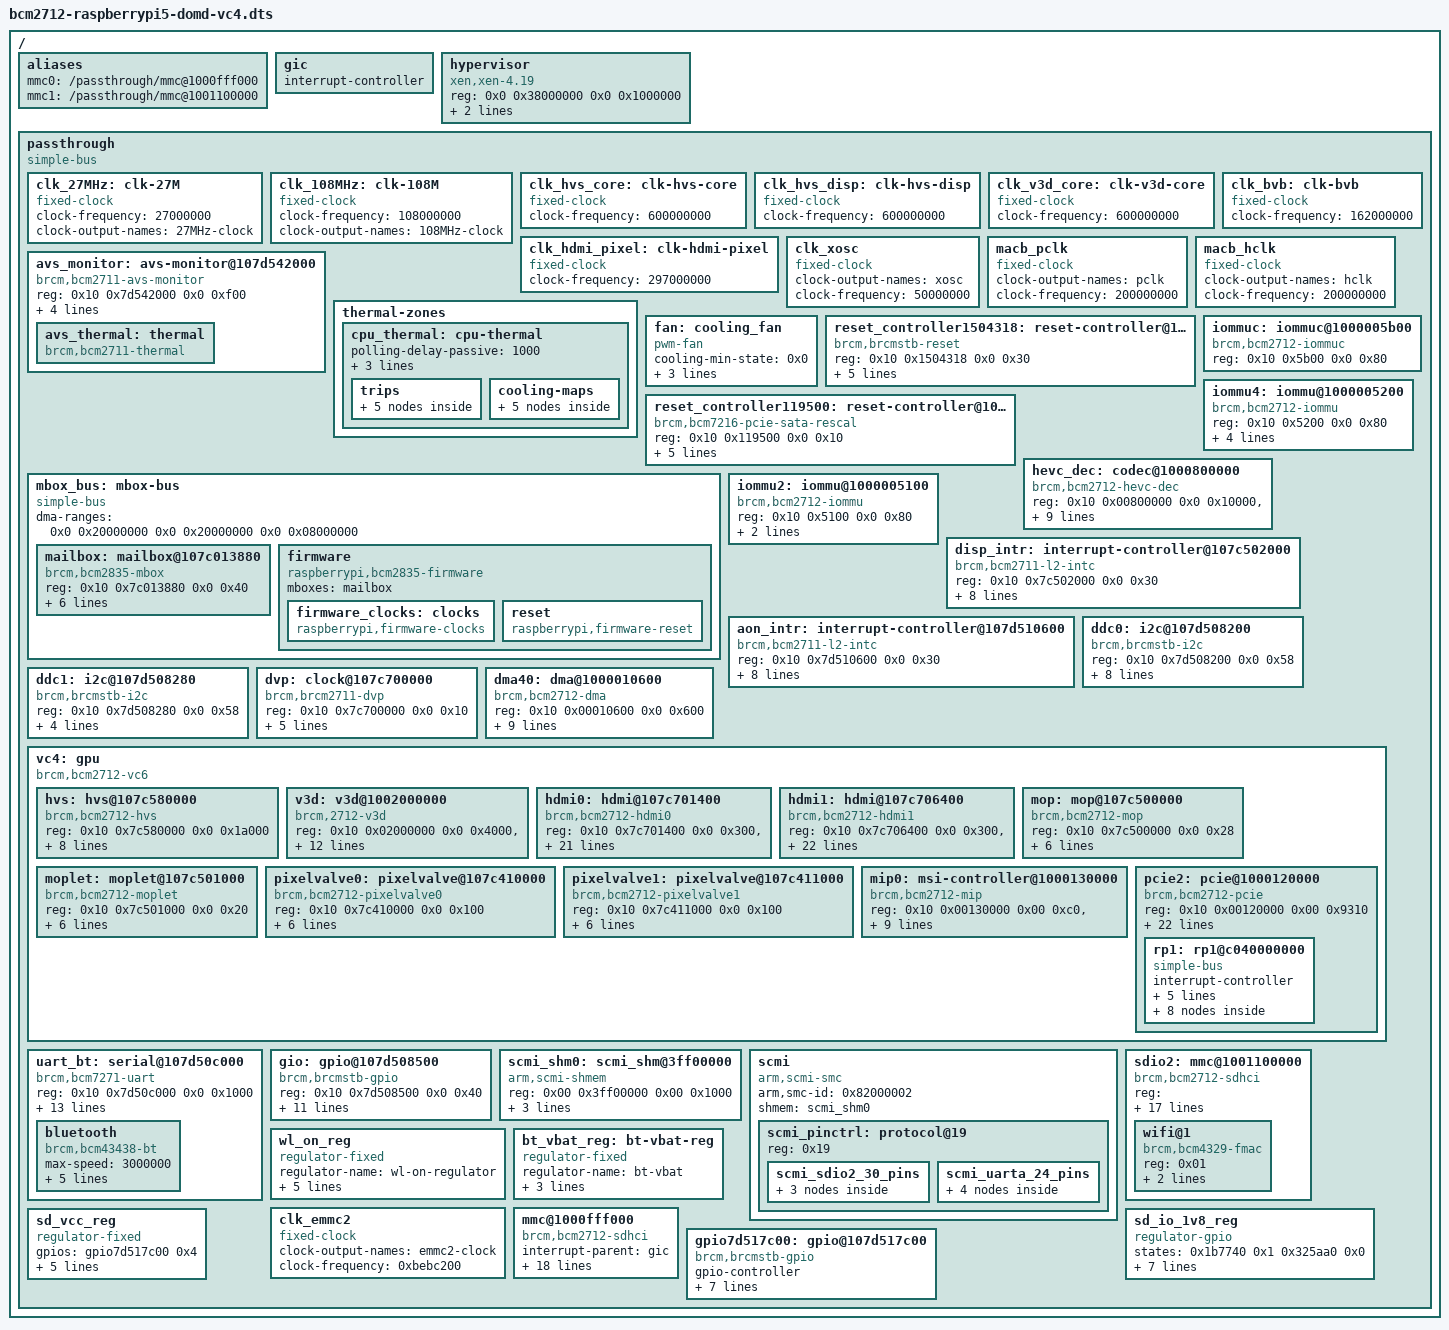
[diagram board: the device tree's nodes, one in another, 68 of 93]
/*
 * BCM2712 RPi5 - DomD VC4 driver domain partial device tree
 *
 * Architecture: thin Dom0 (control; Zephyr by default, or Linux) + Linux DomD
 * (GPU driver) + DomU (AGL cluster) + DomA (AAOS).
 *
 * This DTS is shared by both Dom0 flavours. domd-vc4.bb strips every block
 * between a pair of SODEV-LINUX-DOM0-SD-STRIP markers when DOM0_OS=linux; the
 * comment at the start of each block says why that flavour's DomD must not have
 * it. With DOM0_OS=zephyr (the default) every block stays.
 *
 * Source DT references:
 *   arch/arm64/boot/dts/broadcom/bcm2712.dtsi
 *   arch/arm64/boot/dts/broadcom/bcm2712-ds.dtsi
 *   arch/arm64/boot/dts/broadcom/bcm2712-rpi.dtsi
 *
 * Bus translation:
 *   soc@107c000000 ranges = <0x0 0x10 0x00000000 0x80000000>
 *     -> soc-internal 0x7c...... -> axi level 0x10_7c......
 *   axi: ranges identity, so axi addresses are absolute physical.
 *
 * Address mode (xl iomem + xen,reg):
 *   Identity mapping: guest IPA = host PA.
 *   xen,reg semantics: <host PA size guest IPA size> per Xen partial DT spec.
 *
 * Mailbox ownership: DomD accesses the mailbox directly, so the mailbox node is
 *   kept here and "0x107c013,1" is listed in the domain config's iomem. The
 *   alternative -- proxying mailbox calls through Dom0 -- is not used.
 *
 * Details that are easy to get wrong and are load-bearing here:
 *   - HDMI and HVS interrupts are routed via their L2 controllers (aon_intr and
 *     disp_intr), not directly from the GIC
 *   - the V3D and HVS iomem ranges are the exact register sizes, not rounded up
 *   - all 9 HDMI reg blocks are present (metadata, csc, cec, hd, ...); a missing
 *     block leaves the driver bound but unable to drive that sub-function
 *   - mailbox and firmware sit under mbox-bus, whose bounded dma-ranges keeps
 *     their DMA in the VPU-reachable bank (an empty dma-ranges on the firmware
 *     node itself did nothing)
 *   - disp_intr is SPI 97 (a plausible-looking 44 is wrong)
 */

/dts-v1/;

/ {

	#address-cells = <0x2>;
	#size-cells = <0x2>;

	/* SODEV-LINUX-DOM0-SD-STRIP-BEGIN: domd-vc4.bb strips this node for
	 * DOM0_OS=linux, where DomD has neither of the two mmc controllers it
	 * names: the SD card and the Wi-Fi SDIO controller both stay with the
	 * Linux Dom0. */
	/*
	 * Pin the mmc host numbering.
	 *
	 * Linux assigns mmc indices in probe order unless /aliases pins them,
	 * and the Wi-Fi SDIO controller can win that race:
	 *     mmc1: SDHCI controller on 1000fff000.mmc    <- the SD card
	 *     mmc0: SDHCI controller on 1001100000.mmc    <- the Wi-Fi SDIO
	 *     Waiting for root device /dev/mmcblk0p2...
	 * and DomD hangs in rootwait because root= names the wrong controller.
	 * With `quiet` that message is invisible: the symptom is an
	 * intermittent silent hang about a second into the DomD boot.
	 *
	 * The host DT pins mmc0 the same way. Path strings, not &phandles, so
	 * that this node does not depend on labels the strip blocks remove.
	 */
	aliases {
		mmc0 = "/passthrough/mmc@1000fff000";
		mmc1 = "/passthrough/mmc@1001100000";
	};
	/* SODEV-LINUX-DOM0-SD-STRIP-END */

	gic: gic {
		#interrupt-cells = <0x3>;
		interrupt-controller;
		/*
		 * Hard-code phandle to GUEST_PHANDLE_GIC (= 65000 = 0xfde8) from
		 * xen/include/public/device_tree_defs.h. This fragment is used on
		 * BOTH paths and only libxl constrains the value: domd.cfg names it
		 * in `device_tree =`, libxl does NOT copy this root-level dummy gic
		 * node (only /passthrough + /aliases get copied), and it gives the
		 * GIC node it generates a hard-coded GUEST_PHANDLE_GIC
		 * (make_gicv{2,3}_node()). Every `interrupt-parent = <&gic>` inside
		 * /passthrough is emitted as that phandle value, so a lower one
		 * would dangle there -> DomD kernel IRQ resolution fails -> vc4-drm
		 * bind fails.
		 *
		 * The dom0less path does not constrain it: Xen reads the value back
		 * from this node (init_intc_phandle()) and gives its generated vGIC
		 * the same phandle. Xen 4.22 does reject a fragment whose highest
		 * phandle is in the reserved range ("Device tree generation failed
		 * (-75)" then a panic on domain creation) -- an upstream regression
		 * fixed by xen patch 4.22-0006, not a reason to change this value.
		 */
		phandle = <0xfde8>;
		linux,phandle = <0xfde8>;
	};

	/*
	 * Explicitly add a root-level /hypervisor node. libxl
	 * make_hypervisor_node should auto-generate it, but it may be skipped
	 * on the partial DT path, so inject it explicitly. Linux arm64
	 * xen_early_init() runs of_scan_flat_dt(fdt_find_hyper_node), which
	 * walks the root for the "xen,xen" compatible; finding it here makes
	 * Xen detection succeed -> xen_swiotlb_dma_ops works -> p2m translation
	 * for V3D DMA.
	 *
	 * reg uses the placeholder value libxl defines in dom_xen_4_19.h:
	 * GUEST_GNTTAB_BASE = 0x38000000 (within DomD memory, grant table area)
	 * size = 0x1000000 (16 MB).
	 * Note: the actual grant table location is assigned by libxl, so this
	 * reg is only for Linux Xen detection (node-existence check).
	 */
	hypervisor: hypervisor {
		compatible = "xen,xen-4.19", "xen,xen";
		reg = <0x0 0x38000000 0x0 0x1000000>;
		interrupts = <0x1 0xf 0xf04>;
		interrupt-parent = <&gic>;
	};

	/*
	 * Linux of_platform_default_populate() walks the DT root with
	 * strict=true, requiring each bus to have `compatible` matching
	 * of_default_bus_match_table (simple-bus, simple-mfd, isa, amba-bus)
	 * to enumerate its children as platform_devices. Without this, the
	 * /passthrough subtree (HVS/V3D/HDMI/PV) is never registered, the
	 * corresponding drivers' probe() is never called, and vc4-drm bind
	 * completes with an empty component list -> /dev/dri/card0 not created
	 * -> weston fails to start.
	 *
	 * The dtc warning is build-time only (non-fatal), and libxl
	 * copy_partial_fdt() does NOT inspect bus compatible. The Xen
	 * partial-device-tree spec (xen/docs/misc/arm/passthrough.txt:48)
	 * explicitly mandates `compatible = "simple-bus"` on /passthrough.
	 */
	passthrough: passthrough {
		compatible = "simple-bus";
		ranges;
		#address-cells = <0x2>;
		#size-cells = <0x2>;

		/* Fixed clocks */
		/*
		 * Add the fixed-clock nodes that HDMI audio/cec clocks need.
		 * Upstream BCM2712 defines them at the bcm2712.dtsi root level, but
		 * the partial DT spec allows them under /passthrough (SW-only
		 * fixed-clock, no hardware register needed).
		 *   clk_27MHz  -> HDMI cec clock source
		 *   clk_108MHz -> dvp parent clock (to HDMI audio via dvp)
		 */
		clk_27MHz: clk-27M {
			#clock-cells = <0>;
			compatible = "fixed-clock";
			clock-frequency = <27000000>;
			clock-output-names = "27MHz-clock";
		};

		clk_108MHz: clk-108M {
			#clock-cells = <0>;
			compatible = "fixed-clock";
			clock-frequency = <108000000>;
			clock-output-names = "108MHz-clock";
		};

		/*
		 * The BCM2712 VPU returns a GET_CLOCKS (tag 0x00010007) data format
		 * that mismatches the raspberrypi-clk driver's sanity check, so its
		 * probe fails with -22 (EINVAL) and the firmware_clocks provider is
		 * never registered, leaving every <&firmware_clocks N> reference
		 * from HVS/V3D/HDMI unresolved.
		 *
		 * Pragmatic workaround: turn the primary clocks vc4-drm needs into
		 * fixed-clocks to remove the firmware_clocks dependency entirely.
		 * The driver's devm_clk_get / clk_prepare_enable succeed at probe;
		 * clk_set_rate() returns EINVAL on the fixed-clock side but the
		 * driver only warns and continues. The VPU does the real clock
		 * control at KMS init, so the Linux driver does not need to set a
		 * rate (the display mode keeps the VPU default).
		 */
		clk_hvs_core: clk-hvs-core {
			#clock-cells = <0>;
			compatible = "fixed-clock";
			clock-frequency = <600000000>;   /* HVS core 600 MHz */
		};
		clk_hvs_disp: clk-hvs-disp {
			#clock-cells = <0>;
			compatible = "fixed-clock";
			clock-frequency = <600000000>;   /* HVS disp 600 MHz */
		};
		clk_v3d_core: clk-v3d-core {
			#clock-cells = <0>;
			compatible = "fixed-clock";
			clock-frequency = <600000000>;   /* V3D core 600 MHz */
		};
		clk_hdmi_pixel: clk-hdmi-pixel {
			#clock-cells = <0>;
			compatible = "fixed-clock";
			clock-frequency = <297000000>;   /* HDMI pixel clock 297 MHz (~4K@60) */
		};
		clk_bvb: clk-bvb {
			#clock-cells = <0>;
			compatible = "fixed-clock";
			clock-frequency = <162000000>;   /* HDMI BVB 162 MHz */
		};

		clk_xosc: clk_xosc {
			compatible = "fixed-clock";
			#clock-cells = <0>;
			clock-output-names = "xosc";
			clock-frequency = <50000000>;
		};

		/* RP1 GbE fixed clocks (macb pclk/hclk). clk_xosc (50 MHz) is above. */
		macb_pclk: macb_pclk {
			compatible = "fixed-clock";
			#clock-cells = <0>;
			clock-output-names = "pclk";
			clock-frequency = <200000000>;
		};

		macb_hclk: macb_hclk {
			compatible = "fixed-clock";
			#clock-cells = <0>;
			clock-output-names = "hclk";
			clock-frequency = <200000000>;
		};

		/* =====================================================================
		 * Native-style FAN control (kernel thermal-zone managed; daemon removed)
		 *
		 * The RPi5 active-cooler FAN sits under RP1 (cooling_fan/pwm-fan -> rp1_pwm1
		 * ch3 = GPIO45 FAN_PWM). Native Linux lets the kernel auto-control it via the
		 * SoC AVS temperature sensor (brcm,bcm2711-thermal) -> cpu_thermal thermal-zone
		 * -> cooling-map -> cooling_fan. To reproduce the same scheme in DomD, pass
		 * through the SoC AVS sensor (under avs_monitor) and place the thermal-zone +
		 * cooling_fan in the guest DT.
		 *
		 * Placement: dom0less copies only the partial DT's /passthrough subtree into
		 * the guest DT (dom0less-build.c:407-410 "Only scan .../passthrough, ignore the
		 * rest"), so all nodes, including thermal-zones, are placed under /passthrough.
		 * 6.18 thermal_of does a whole-tree name search via
		 * of_find_node_by_name(NULL,"thermal-zones") (thermal_of.c:130), so it can find
		 * them even under /passthrough.
		 * ===================================================================== */

		/* SoC AVS thermal sensor. brcm,bcm2711-thermal binds using only the parent's
		 * (avs_monitor=syscon) regmap, with zero clocks/power-domain/reset dependency
		 * and no IRQ (polling). host PA = axi 0x10_7d542000 (soc@107c000000 ranges
		 * translation). The thin Dom0 does not use thermal and cooling_fan (RP1) is
		 * already passed through, so taking this sensor for DomD does not affect Dom0 boot. */
		avs_monitor: avs-monitor@107d542000 {
			compatible = "brcm,bcm2711-avs-monitor", "syscon", "simple-mfd";
			reg = <0x10 0x7d542000 0x0 0xf00>;
			status = "okay";
			xen,path = "/soc@107c000000/avs-monitor@7d542000";
			xen,force-assign-without-iommu;
			xen,reg = <0x10 0x7d542000 0x0 0x1000 0x10 0x7d542000>;

			avs_thermal: thermal {
				compatible = "brcm,bcm2711-thermal";
				#thermal-sensor-cells = <0x0>;
			};
		};

		/* cpu_thermal thermal-zone (same values as native bcm2712-ds.dtsi +
		 * bcm2712-rpi-5-b.dts). coefficients are written as the same-byte hex as the
		 * host DTB. The thermal governor (step_wise) controls the FAN duty via the
		 * cooling-map according to temperature. */
		thermal-zones {
			cpu_thermal: cpu-thermal {
				polling-delay-passive = <1000>;
				polling-delay = <1000>;
				coefficients = <0xfffffdda 0x6ddd0>;   /* = <(-550) 450000> */
				thermal-sensors = <&avs_thermal>;

				trips {
					cpu_tepid: cpu-tepid {
						temperature = <50000>;
						hysteresis = <5000>;
						type = "active";
					};
					cpu_warm: cpu-warm {
						temperature = <60000>;
						hysteresis = <5000>;
						type = "active";
					};
					cpu_hot: cpu-hot {
						temperature = <67500>;
						hysteresis = <5000>;
						type = "active";
					};
					cpu_vhot: cpu-vhot {
						temperature = <75000>;
						hysteresis = <5000>;
						type = "active";
					};
					cpu_crit: cpu-crit {
						temperature = <110000>;
						hysteresis = <0>;
						type = "critical";
					};
				};

				cooling-maps {
					tepid {
						trip = <&cpu_tepid>;
						cooling-device = <&fan 1 1>;
					};
					warm {
						trip = <&cpu_warm>;
						cooling-device = <&fan 2 2>;
					};
					hot {
						trip = <&cpu_hot>;
						cooling-device = <&fan 3 3>;
					};
					vhot {
						trip = <&cpu_vhot>;
						cooling-device = <&fan 4 4>;
					};
					melt {
						trip = <&cpu_crit>;
						cooling-device = <&fan 4 4>;
					};
				};
			};
		};

		/* Active-cooler FAN (pwm-fan). Referenced as a cooling-device from the
		 * cooling-map; the kernel thermal governor controls the duty of rp1_pwm1
		 * ch3 (GPIO45) according to temperature. pwms = <&rp1_pwm1 ch period polarity>.
		 * The partial DT does not include the dt-bindings macros, so values are written
		 * numerically (period 41566ns ~24kHz, polarity 1 = PWM_POLARITY_INVERTED).
		 * pwm-fan has no MMIO and uses the already-passed-through RP1 PWM via pwms, so
		 * xen,reg is not needed. tacho (rpm-regmap/rpm-offset) is omitted (RPM telemetry
		 * only, not needed for FAN control). */
		fan: cooling_fan {
			compatible = "pwm-fan";
			#cooling-cells = <0x2>;
			cooling-min-state = <0x0>;
			cooling-max-state = <0x3>;
			cooling-levels = <0 75 125 175 250>;
			pwms = <&rp1_pwm1 3 41566 1>;
			status = "okay";
		};

		/* PCIe reset controllers: real host PA -> correct literal xen,reg (unlike the
		 * RP1 sub-device 0xc0_40.. addresses). pcie2 resets= references these. */
		reset_controller1504318: reset-controller@1001504318 {
			compatible = "brcm,brcmstb-reset";
			#reset-cells = <0x1>;
			reg = <0x10 0x1504318 0x0 0x30>;
			xen,path = "/soc@107c000000/reset-controller@1504318";
			xen,force-assign-without-iommu;
			xen,reg = <0x10 0x1504000 0x0 0x1000 0x10 0x1504000>;
		};

		reset_controller119500: reset-controller@1000119500 {
			compatible = "brcm,bcm7216-pcie-sata-rescal";
			#reset-cells = <0x0>;
			reg = <0x10 0x119500 0x0 0x10>;
			xen,path = "/soc@107c000000/reset-controller@119500";
			xen,force-assign-without-iommu;
			xen,reg = <0x10 0x119000 0x0 0x1000 0x10 0x119000>;
		};

		/* ===== Mailbox + firmware (Option II) =====
		 * raspberrypi-clk probe -22 / vc4 "Couldn't stop firmware display: -22"
		 * ROOT CAUSE (confirmed): the firmware property buffer is allocated from the
		 * MAILBOX platform device (raspberrypi.c:103 dma_alloc_coherent(fw->chan->
		 * mbox->dev)). The VideoCore (VPU) can only DMA the low <1GB of machine RAM,
		 * but DomD's xen,static-mem banks place coherent allocs in a high bank the VPU
		 * cannot write -> the response status word buf[1] never becomes
		 * RPI_FIRMWARE_STATUS_SUCCESS(0x80000000), so rpi_firmware_property_list returns
		 * -EINVAL for EVERY property request (GET_CLOCKS, display-stop, ...).
		 * FIX: wrap mailbox+firmware in an intermediate simple-bus carrying a BOUNDED
		 * dma-ranges that caps this device's dma_alloc_coherent to the only VPU-reachable
		 * machine bank (0x20000000-0x27ffffff). `ranges;` keeps MMIO identity-mapped; only
		 * DMA is constrained, and only for mailbox+firmware (other passthrough devices keep
		 * their own dma-ranges). of_dma_configure picks this up -> dev->bus_dma_limit =
		 * 0x28000000 -> dma_direct_alloc forces the buffer into the low bank the VPU sees.
		 * (The previous empty `dma-ranges;` on the firmware node was a no-op: the kernel
		 * ignores empty dma-ranges, and the alloc device is the mailbox, not firmware.)
		 * NOTE: V3D/HVS/HDMI deliberately KEEP their fixed-clock refs below (safe display
		 * path); once HW confirms raspberrypi-clk now probes, a later step can switch them
		 * to <&firmware_clocks N> for native busy/idle DVFS.
		 */
		mbox_bus: mbox-bus {
			compatible = "simple-bus";
			#address-cells = <0x2>;
			#size-cells = <0x2>;
			ranges;
			dma-ranges = <0x0 0x20000000 0x0 0x20000000 0x0 0x08000000>;

			mailbox: mailbox@107c013880 {
				compatible = "brcm,bcm2835-mbox";
				reg = <0x10 0x7c013880 0x0 0x40>;
				interrupts = <0x0 0x21 0x4>;  /* GIC SPI 33 LEVEL_HIGH */
				interrupt-parent = <&gic>;
				#mbox-cells = <0>;
				xen,path = "/soc@107c000000/mailbox@7c013880";
				xen,force-assign-without-iommu;
				xen,reg = <0x10 0x7c013000 0x0 0x1000 0x10 0x7c013000>;
			};

			firmware: firmware {
				compatible = "raspberrypi,bcm2835-firmware", "simple-mfd";
				#address-cells = <0x1>;
				#size-cells = <0x1>;
				mboxes = <&mailbox>;

				firmware_clocks: clocks {
					compatible = "raspberrypi,firmware-clocks";
					#clock-cells = <0x1>;
				};

				reset: reset {
					compatible = "raspberrypi,firmware-reset";
					#reset-cells = <0x1>;
				};
			};
		};

		/* ===== IOMMU (HVS DMA mapping) ===== */
		iommuc: iommuc@1000005b00 {
			compatible = "brcm,bcm2712-iommuc";
			reg = <0x10 0x5b00 0x0 0x80>;
			/* dom0less requires xen,reg on a node that has xen,path
			 * (dom0less-build.c:481 `xen_path && !xen_reg` -> -EINVAL -22).
			 * iommuc (0x5b00) is in the same page (0x5000) as iommu4, whose
			 * xen,reg already maps the entire 0x5000 page. So strip all
			 * passthrough properties from iommuc to make it a plain node: it
			 * is copied to the guest DT (so the &iommuc phandle in iommu4's
			 * cache= resolves), its iomem is covered by iommu4's page, and a
			 * double map (overlap -22) is avoided. */
		};

		iommu4: iommu@1000005200 {
			compatible = "brcm,bcm2712-iommu";
			reg = <0x10 0x5200 0x0 0x80>;
			cache = <&iommuc>;
			#iommu-cells = <0x0>;
			#interconnect-cells = <0x0>;
			xen,path = "/axi/iommu@5200";
			xen,force-assign-without-iommu;
			/* page-align 0x5200->0x5000 (dom0less requires a page-aligned
			 * xen,reg base). This 0x5000 page contains both iommu4 (0x5200)
			 * and iommuc (0x5b00). */
			xen,reg = <0x10 0x5000 0x0 0x1000 0x10 0x5000>;
		};

		/* SODEV-LINUX-DOM0-SD-STRIP-BEGIN: domd-vc4.bb strips the HEVC decoder and
		 * its IOMMU for DOM0_OS=linux as well. That flavour gives DomA no hardware
		 * decoder (rpi5-sodev.yaml's linux flavour sets XT_DOMA_HWDEC_VULKAN to
		 * false and says why), so DomD has no user for the block. Nothing outside
		 * this pair refers to hevc_dec or
		 * iommu2.
		 */
		/* ===== HEVC decoder (rpi-hevc-dec) =====
		 * Beside the IOMMUs, as codec@800000 sits directly under /axi on the
		 * host, and not inside the gpu node, whose children are vc4's.
		 *
		 * BCM2712's only video decode block. There is NO H.264 hardware on this SoC:
		 * the shipped bcm2712-rpi-5-b.dtb has 0 occurrences of vchiq (against
		 * bcm2711-rpi-4-b.dtb's 2) and bcm2835-codec reaches the VideoCore H.264
		 * decoder only over VCHIQ, so that driver has nothing to bind to here. HEVC is
		 * a separate, directly addressable block, which is why this node exists.
		 *
		 * Driver: drivers/media/platform/raspberrypi/hevc_dec (module rpi-hevc-dec,
		 * CONFIG_VIDEO_RPI_HEVC_DEC=m in bcm2712_defconfig:1025). It is a STATELESS
		 * V4L2 decoder -- media_device_register() at hevc_d.c:281 means it also creates
		 * /dev/mediaN -- and DomA cannot consume it directly: virtio-media has no
		 * media-device or request-fd concept, so the device model presents a
		 * stateful decoder and drives this one through libavcodec (qemu patch
		 * 0217). This node only gives DomD the hardware.
		 *
		 * ALL THREE PROPERTY GROUPS ARE LOAD-BEARING. hevc_d_hw_probe returns the error
		 * unchanged if any of them fails, so a missing one is a silent no-device:
		 *   reg/reg-names  devm_platform_ioremap_resource_byname("hevc"/"intc"),
		 *                  hevc_d_hw.c:391,387
		 *   clocks         devm_clk_get(dev, NULL) at hevc_d_hw.c:395 -- a hard
		 *                  failure, not a warning. RPI_FIRMWARE_HEVC_CLK_ID = 11
		 *                  (raspberrypi-firmware.h, the enum starts at EMMC = 1) and
		 *                  clk-raspberrypi.c:32,147 does export it. firmware_clocks
		 *                  rather than a fixed-clock because raspberrypi-clk probes on
		 *                  this board now (see the v3d note in the gpu node); if
		 *                  that regresses, the HVS pattern (<&clk_*>) is the
		 *                  fallback, since the driver takes its real rate from the
		 *                  mailbox (rpi_firmware_clk_get_max_rate, hevc_d_hw.c:361)
		 *                  and not from this clk at all.
		 *   interrupts     platform_get_irq(pdev, 0), hevc_d_hw.c:407. SPI 98 -> abs
		 *                  IRQ 130.
		 *
		 * rpi_firmware_find_node() needs the mailbox, which this DT already passes
		 * through (mbox-bus/mailbox@107c013880) -- that is why no new firmware
		 * plumbing appears here.
		 */
		hevc_dec: codec@1000800000 {
			compatible = "brcm,bcm2712-hevc-dec",
				     "raspberrypi,hevc-dec";
			reg = <0x10 0x00800000 0x0 0x10000>,
			      <0x10 0x00840000 0x0 0x01000>;
			reg-names = "hevc", "intc";
			clocks = <&firmware_clocks 11>;   /* RPI_FIRMWARE_HEVC_CLK_ID */
			clock-names = "hevc";
			interrupts = <0x0 0x62 0x4>;      /* GIC SPI 98 -> abs IRQ 130 */
			interrupt-parent = <&gic>;
			/* iommus = <&iommu2>;  -- DELIBERATELY NOT SET. See below.
			 *
			 * The host node is behind iommu@5100, but in a Xen guest this property
			 * makes the decoder unprobeable. Measured:
			 *   bcm2712-iommu 1000005100.iommu: IOVA aperture 0xa00000000..0xb00000000
			 *   platform 1000800000.codec: bcm2712_iommu_attach_dev: MMU 1000005100.iommu
			 *   ... WARNING at dma_set_mask+0x10c, lr hevc_d_probe+0x13c
			 *   rpi-hevc-dec 1000800000.codec: Failed dma_set_mask_and_coherent
			 *   rpi-hevc-dec 1000800000.codec: probe ... failed with error -5
			 *
			 * The WARN is dma_supported()'s WARN_ON(ops && use_dma_iommu(dev)): the two
			 * DMA paths are mutually exclusive, and a Xen guest already has one. Xen
			 * installs xen_swiotlb_dma_ops on EVERY device in a direct-mapped domain, so
			 * as soon as the IOMMU also claims the device dma_supported() refuses and
			 * dma_set_mask_and_coherent() returns -EIO. hevc_d_probe() treats that as
			 * fatal, so there is no /dev/video* at all and nothing for qemu's
			 * virtio-media v4l2-device= to proxy.
			 *
			 * Why this is not a problem for the GPU, which keeps its iommus (see
			 * <&iommu4> on the gpu node): vc4 never calls dma_set_mask_and_coherent, so
			 * it never reaches the check. The collision is latent there too.
			 *
			 * Dropping the property puts the decoder on the plain (xen-swiotlb) path.
			 * That is consistent with xen,force-assign-without-iommu just below -- Xen
			 * is not programming an IOMMU for this device either way -- and DomD is
			 * direct-mapped, so its DMA addresses are real physical addresses. All of
			 * DomD's static-mem banks end at 0x1c0000000 (7 GiB), well inside the
			 * DMA_BIT_MASK(36) the driver asks for.
			 *
			 * IF THE DECODER PROBES BUT PRODUCES GARBAGE, that is the signal that the
			 * block cannot reach those addresses without the MMU, and the fix moves to
			 * the kernel: stop arch_setup_dma_ops()/xen_setup_dma_ops() from installing
			 * swiotlb ops on a device that has an IOMMU, which is the real upstream bug
			 * here. Do not simply put this property back.
			 */
			xen,path = "/axi/codec@800000";
			xen,force-assign-without-iommu;
			/* Both reg blocks are already page-aligned and a whole number of
			 * pages (0x800000/0x10000 = 16, 0x840000/0x1000 = 1), so unlike
			 * v3d's sms block no rounding is needed. */
			xen,reg = <0x10 0x00800000 0x0 0x10000 0x10 0x00800000>,
				  <0x10 0x00840000 0x0 0x01000 0x10 0x00840000>;
			status = "okay";
		};

		/* iommu2 (0x5100) is the IOMMU the HEVC decoder sits behind: the host
		 * codec@800000 has iommus = <&iommu2>, verified by resolving phandle 0x49 in
		 * the decompiled bcm2712-rpi-5-b.dtb to iommu@5100. The decoder node above
		 * does not reference it; what the node is here for is DomD's bcm2712-iommu
		 * driver, whose probe (bcm2712_iommu_init) puts this MMU into a known state:
		 * enabled, translating only its IOVA aperture, which starts at 0xa00000000,
		 * and passing every lower address through unchanged. DomD's memory ends at
		 * 0x1c0000000, so the decoder's DMA reaches it untranslated. Same treatment
		 * as iommuc above -- 0x5100 is in the 0x5000 page that iommu4's xen,reg
		 * already maps, so this stays a plain node with no passthrough properties of
		 * its own, which is what avoids a double map (overlap -22). aperture-size is
		 * the host node's value. */
		iommu2: iommu@1000005100 {
			compatible = "brcm,bcm2712-iommu";
			reg = <0x10 0x5100 0x0 0x80>;
			cache = <&iommuc>;
			aperture-size = <0x1 0x00000000>;
			#iommu-cells = <0x0>;
		};
		/* SODEV-LINUX-DOM0-SD-STRIP-END */

		/* ===== Display interrupt controller (L2 intc) =====
		 * source: bcm2712.dtsi disp_intr: interrupt-controller@7c502000
		 * GIC SPI 97 LEVEL_HIGH, #interrupt-cells = <1>
		 */
		disp_intr: interrupt-controller@107c502000 {
			compatible = "brcm,bcm2711-l2-intc", "brcm,l2-intc";
			reg = <0x10 0x7c502000 0x0 0x30>;
			interrupts = <0x0 0x61 0x4>;   /* GIC SPI 97 LEVEL_HIGH */
			interrupt-parent = <&gic>;
			interrupt-controller;
			#interrupt-cells = <0x1>;
			xen,path = "/soc@107c000000/interrupt-controller@7c502000";
			xen,force-assign-without-iommu;
			xen,reg = <0x10 0x7c502000 0x0 0x1000 0x10 0x7c502000>;
		};

		/* ===== Always-on interrupt controller (HDMI parent) =====
		 * source: bcm2712.dtsi aon_intr: interrupt-controller@7d510600
		 * GIC SPI 239 LEVEL_HIGH, #interrupt-cells = <1>
		 */
		aon_intr: interrupt-controller@107d510600 {
			compatible = "brcm,bcm2711-l2-intc", "brcm,l2-intc";
			reg = <0x10 0x7d510600 0x0 0x30>;
			interrupts = <0x0 0xef 0x4>;   /* GIC SPI 239 LEVEL_HIGH */
			interrupt-parent = <&gic>;
			interrupt-controller;
			#interrupt-cells = <0x1>;
			xen,path = "/soc@107c000000/interrupt-controller@7d510600";
			xen,force-assign-without-iommu;
			/* page-align 0x7d510600->0x7d510000 (dom0less page boundary).
			 * The 0x7d510000 page contains aon_intr (0x7d510600). */
			xen,reg = <0x10 0x7d510000 0x0 0x1000 0x10 0x7d510000>;
		};

		/* ===== ddc0 / ddc1 i2c (HDMI EDID readback) =====
		 * The `ddc` property name resolves correctly, but with
		 * status="disabled" the brcmstb-i2c driver does not bind and
		 * of_find_i2c_adapter_by_node() returns NULL -> a silent
		 * -EPROBE_DEFER loop, so HDMI cannot bind. Use status="okay" with
		 * full passthrough (clocks + interrupts + xen,reg). Sub-IRQs 14/15
		 * are chosen (no conflict with HVS 2/9/16).
		 */
		ddc0: i2c@107d508200 {
			compatible = "brcm,brcmstb-i2c";
			reg = <0x10 0x7d508200 0x0 0x58>;
			clock-frequency = <97500>;
			clocks = <&clk_27MHz>;
			interrupt-parent = <&disp_intr>;
			interrupts = <14>;
			#address-cells = <1>;
			#size-cells = <0>;
			status = "okay";
			xen,path = "/soc@107c000000/i2c@7d508200";
			xen,force-assign-without-iommu;
			/* page-align 0x7d508200->0x7d508000 (dom0less page boundary).
			 * The 0x7d508000 page contains both ddc0 (0x7d508200) and ddc1
			 * (0x7d508280). */
			xen,reg = <0x10 0x7d508000 0x0 0x1000 0x10 0x7d508000>;
		};

		ddc1: i2c@107d508280 {
			compatible = "brcm,brcmstb-i2c";
			reg = <0x10 0x7d508280 0x0 0x58>;
			clock-frequency = <97500>;
			clocks = <&clk_27MHz>;
			interrupt-parent = <&disp_intr>;
			interrupts = <15>;
			#address-cells = <1>;
			#size-cells = <0>;
			status = "okay";
			/* dom0less requires xen,reg on a node that has xen,path
			 * (dom0less-build.c:481 `xen_path && !xen_reg` -> -EINVAL -22).
			 * ddc1 (0x7d508280) is in the same page (0x7d508000) as ddc0,
			 * whose xen,reg already maps the page. So strip all passthrough
			 * properties from ddc1 to make it a plain node: it is copied to
			 * the guest DT (so the &ddc1 phandle in hdmi1's ddc= resolves),
			 * its iomem is covered by ddc0's page, and a double map is
			 * avoided. */
		};

		/* ===== dvp (Display VPU): HDMI audio clock + reset provider =====
		 * vc4_hdmi (the BCM2712 path = vc5_hdmi_init_resources) requires
		 * audio / cec / reset:
		 *   devm_clk_get(dev, "audio") <- &dvp 0
		 *   devm_clk_get(dev, "cec")   <- &clk_27MHz
		 *   devm_reset_control_get(dev, NULL) <- &dvp 1|2
		 * dvp is an MMIO-based clock + reset controller (brcm,brcm2711-dvp).
		 * reg = 0x107c700000 (16 bytes; already within the HDMI shared csc
		 * iomem "0x107c700,1" page, so no extra iomem is needed).
		 */
		dvp: clock@107c700000 {
			compatible = "brcm,brcm2711-dvp";
			reg = <0x10 0x7c700000 0x0 0x10>;
			clocks = <&clk_108MHz>;
			#clock-cells = <1>;
			#reset-cells = <1>;
			xen,path = "/soc@107c000000/clock@7c700000";
			xen,force-assign-without-iommu;
			xen,reg = <0x10 0x7c700000 0x0 0x1000 0x10 0x7c700000>;
		};

		/* ===== DMA40 (40-bit DMA controller): HDMI audio =====
		 * vc4_hdmi_audio_init() bails out early ("'dmas' DT property is missing
		 * or empty, no HDMI audio") unless the hdmi node carries a dmas phandle,
		 * and it returns 0 so the display still probes -- which is why the
		 * missing ASoC card went unnoticed for so long
		 * (drivers/gpu/drm/vc4/vc4_hdmi.c).
		 *
		 * The host node is /axi/dma@10600. Its reg base 0x10600 is channel 6
		 * (BCM2835_DMA_CHAN(n) = n << 8, counted from the 0x10000 base), so this
		 * 0x600 window covers channels 6..11 and the six SPIs below are
		 * dma6..dma11.
		 *
		 * brcm,dma-channel-mask is deliberately narrower than the host:
		 *   host DTB file    0x7c0  (ch 6-10)  <- pre-fixup value, do NOT use
		 *   host at runtime  0xf80  (ch 7-11)  <- firmware reserves ch6 for itself
		 *   here             0x400  (ch10 only)
		 * A passthrough DT should expose the minimum, and HDMI1 audio is the only
		 * consumer in DomD. ch10 is also the channel that was verified on this
		 * hardware, both bare metal and under Xen.
		 *
		 * REQUIRES the host DT overlay to mark this node xen,passthrough
		 * (bcm2712-raspberrypi5-xen.dtso). Without it Xen keeps the IRQs for Dom0
		 * and DomD dies at boot with:
		 *   (XEN) IRQ 118 is already used by domain 0
		 *   (XEN) Panic on CPU 0: Failed to allocate requested IRQ 118
		 *
		 * xen,reg is page-aligned down to 0x10000/0x1000, which covers
		 * 0x10600+0x600.
		 */
		dma40: dma@1000010600 {
			compatible = "brcm,bcm2712-dma";
			reg = <0x10 0x00010600 0x0 0x600>;
			interrupts = <0x0 0x56 0x4>,   /* GIC SPI 86 = dma6  */
				     <0x0 0x57 0x4>,   /* GIC SPI 87 = dma7  */
				     <0x0 0x58 0x4>,   /* GIC SPI 88 = dma8  */
				     <0x0 0x59 0x4>,   /* GIC SPI 89 = dma9  */
				     <0x0 0x5a 0x4>,   /* GIC SPI 90 = dma10 */
				     <0x0 0x5b 0x4>;   /* GIC SPI 91 = dma11 */
			interrupt-names = "dma6", "dma7", "dma8",
					  "dma9", "dma10", "dma11";
			interrupt-parent = <&gic>;
			#dma-cells = <1>;
			brcm,dma-channel-mask = <0x400>;
			xen,path = "/axi/dma@10600";
			xen,force-assign-without-iommu;
			xen,reg = <0x10 0x00010000 0x0 0x1000 0x10 0x00010000>;
			status = "okay";
		};

		/* ===== vc4 aggregate =====
		 * The Linux drm/vc4 `bcm2712-vc6` driver walks HVS/V3D/HDMI with
		 * for_each_child_of_node() to probe them, so they must sit directly
		 * under the vc4 (gpu) node. With them as siblings the probe fails
		 * (weston dependency error). The gpu node is a proper aggregate
		 * (#address-cells=2 / #size-cells=2 / ranges identity) with
		 * HVS / V3D / HDMI0 / HDMI1 as children.
		 *
		 * empty `ranges` = identity mapping (child reg is absolute address),
		 * consistent with the xl iomem grant (iomem= on the passthrough parent).
		 */
		vc4: gpu {
			/*
			 * Also list `simple-bus` on the vc4 aggregate.
			 * compatible="brcm,bcm2712-vc6" binds the vc4_drv aggregate
			 * driver, but of_platform does not enumerate children. Adding
			 * `simple-bus` as a fallback compatible makes
			 * of_platform_bus_create() register the children (HVS/V3D/HDMI/PV)
			 * as platform_devices -> component_match_add completes vc4-drm.
			 */
			compatible = "brcm,bcm2712-vc6", "simple-bus";
			#address-cells = <2>;
			#size-cells = <2>;
			ranges;
			status = "okay";

			/* ===== HVS (Display compositor) ===== */
			hvs: hvs@107c580000 {
				compatible = "brcm,bcm2712-hvs";
				reg = <0x10 0x7c580000 0x0 0x1a000>;
				/*
				 * firmware_clocks fails to register, so reference
				 * fixed-clocks instead. vc4_hvs.c:2049 devm_clk_get(dev,
				 * "core"/"disp") then gets a fixed-clock and probe succeeds;
				 * the VPU does the real clock control at boot, so the Linux
				 * driver does not need to set a rate.
				 */
				clocks = <&clk_hvs_core>, <&clk_hvs_disp>;
				clock-names = "core", "disp";
				interrupt-parent = <&disp_intr>;
				interrupts = <2>, <9>, <16>;
				interrupt-names = "ch0-eof", "ch1-eof", "ch2-eof";
				iommus = <&iommu4>;
				/* In the host DT hvs is at ROOT level /hvs@107c580000
				 * (iommu/v3d are under /axi but hvs is not). dom0less
				 * resolves xen,path strictly against the host DT, so an
				 * /axi/ prefix gives "Couldn't find node in host_dt!" -> -22.
				 * The host bcm2712-rpi-5-b.dtb __symbols__ confirms
				 * hvs = "/hvs@107c580000". */
				xen,path = "/hvs@107c580000";
				xen,force-assign-without-iommu;
				xen,reg = <0x10 0x7c580000 0x0 0x1a000 0x10 0x7c580000>;
			};

			/* ===== V3D (3D acceleration) =====
			 * Three separate reg blocks (hub + core0 + sms), each at its exact
			 * size rather than one rounded-up range.
			 */
			v3d: v3d@1002000000 {
				compatible = "brcm,2712-v3d";
				reg = <0x10 0x02000000 0x0 0x4000>,
				      <0x10 0x02008000 0x0 0x6000>,
				      <0x10 0x02030800 0x0 0x0700>;
				reg-names = "hub", "core0", "sms";
				/* Stage 2 (native dynamic V3D clock): now that raspberrypi-clk
				 * probes (mbox-bus dma-ranges fix, confirmed on HW: fw-clk-v3d
				 * registered + driver bound), reference the firmware V3D clock
				 * (RPI_FIRMWARE_V3D_CLK_ID=5) instead of the fixed-clock. clk-
				 * raspberrypi marks the V3D variant .maximize=true, so on v3d
				 * runtime-PM resume (clk_prepare) the firmware is asked for
				 * v3d_freq(=960MHz max) and on idle (clk_unprepare) it drops to
				 * v3d_freq_min -> native busy-960/idle-min DVFS (lower idle
				 * heat/power than constant 960, also eases the USB power budget).
				 * HVS/HDMI keep their fixed-clocks (display clocks, no DVFS gain,
				 * and the audio dvp clock is not wired here). To revert to the
				 * safe constant path, restore <&clk_v3d_core>. */
				clocks = <&firmware_clocks 5>;
				clock-names = "v3d";
				/*
				 * v3d_drv.c tries devm_reset_control_get_exclusive() and on
				 * failure falls back to requesting bridge regs. Referencing
				 * the firmware reset controller via the resets property makes
				 * the reset get succeed, so probe succeeds without bridge
				 * regs. The firmware reset child (compatible =
				 * "raspberrypi,firmware-reset") exists in the partial DT;
				 * BCM2835_RESET_V3D = 0.
				 */
				resets = <&reset 0>;   /* BCM2835_RESET_V3D */
				interrupts = <0x0 0xfa 0x4>,   /* GIC SPI 250 */
					     <0x0 0xf9 0x4>;   /* GIC SPI 249 */
				interrupt-parent = <&gic>;
				xen,path = "/axi/v3d@2000000";
				xen,force-assign-without-iommu;
				/* 3 reg blocks, separate xen,reg entries.
				 * page-align the sms base (0x2030800->0x2030000): dom0less
				 * requires a page-aligned xen,reg base (the real sms reg
				 * 0x2030800/0x700 fits within the 0x2030000 page, so cover it
				 * with 0x2030000/0x1000). Matches domd.cfg iomem
				 * "0x1002030,1". */
				xen,reg = <0x10 0x02000000 0x0 0x4000 0x10 0x02000000>,
					  <0x10 0x02008000 0x0 0x6000 0x10 0x02008000>,
					  <0x10 0x02030000 0x0 0x1000 0x10 0x02030000>;
				status = "okay";
			};

			/* ===== HDMI0 =====
			 * 9 reg blocks: hdmi + dvp + phy + rm + packet + metadata + csc + cec + hd
			 * interrupts via aon_intr (L2 controller), cell values 1,2,3,7,8
			 */
			hdmi0: hdmi@107c701400 {
				compatible = "brcm,bcm2712-hdmi0";
				reg = <0x10 0x7c701400 0x0 0x300>,
				      <0x10 0x7c701000 0x0 0x200>,
				      <0x10 0x7c701d00 0x0 0x300>,
				      <0x10 0x7c702000 0x0 0x80>,
				      <0x10 0x7c703800 0x0 0x200>,
				      <0x10 0x7c704000 0x0 0x800>,
				      <0x10 0x7c700100 0x0 0x80>,
				      <0x10 0x7d510800 0x0 0x100>,
				      <0x10 0x7c720000 0x0 0x100>;
				reg-names = "hdmi", "dvp", "phy", "rm", "packet",
					    "metadata", "csc", "cec", "hd";
				/*
				 * Required clocks: audio (&dvp 0) + cec (&clk_27MHz) +
				 * resets (&dvp 1). The primary hdmi/bvb clocks are also
				 * fixed-clocks (firmware_clocks is absent due to the
				 * raspberrypi-clk probe -22).
				 */
				clocks = <&clk_hdmi_pixel>, <&clk_bvb>,
					 <&dvp 0>, <&clk_27MHz>;
				clock-names = "hdmi", "bvb", "audio", "cec";
				resets = <&dvp 1>;
				/*
				 * The Yocto-built vc4_hdmi.c uses the downstream RPi pattern
				 * of_parse_phandle(dev->of_node, "ddc", 0); the upstream
				 * mainline "ddc-i2c-bus" name does not match and gives
				 * -ENODEV. List both properties for downstream + upstream
				 * compatibility.
				 */
				ddc = <&ddc0>;           /* downstream RPi kernel (actual Yocto build) */
				ddc-i2c-bus = <&ddc0>;   /* upstream Linux mainline compatibility */
				interrupt-parent = <&aon_intr>;
				interrupts = <1>, <2>, <3>, <7>, <8>;
				interrupt-names = "cec-tx", "cec-rx", "cec-low",
						  "hpd-connected", "hpd-removed";
				xen,path = "/soc@107c000000/hdmi@7c701400";
				xen,force-assign-without-iommu;
				/* HDMI0 main reg block (5 contiguous + 1 metadata) and
				 * shared csc/cec/hd (shared with HDMI1 at a different
				 * offset). Pass each through as a separate xen,reg pair.
				 * Add the shared hd page 0x7c720000 (the vc4_hdmi "hd"
				 * reg-name = HDMITX top, must be ioremap'd). csc (0x7c700100)
				 * is in the clock node's 0x7c700000 page; cec (0x7d510800) is
				 * already mapped by aon_intr's 0x7d510000 page. hd is shared
				 * by both HDMI, so map it only once in hdmi0 (re-mapping in
				 * hdmi1 would double-map the same MFN->GPA, overlap -22).
				 * Matches domd.cfg iomem
				 * "0x107c701,3"+"0x107c704,1"+"0x107c720,1".
				 */
				xen,reg = <0x10 0x7c701000 0x0 0x3000 0x10 0x7c701000>,
					  <0x10 0x7c704000 0x0 0x1000 0x10 0x7c704000>,
					  <0x10 0x7c720000 0x0 0x1000 0x10 0x7c720000>;
				status = "okay";
			};

			/* ===== HDMI1 ===== */
			hdmi1: hdmi@107c706400 {
				compatible = "brcm,bcm2712-hdmi1";
				reg = <0x10 0x7c706400 0x0 0x300>,
				      <0x10 0x7c706000 0x0 0x200>,
				      <0x10 0x7c706d00 0x0 0x300>,
				      <0x10 0x7c707000 0x0 0x80>,
				      <0x10 0x7c708800 0x0 0x200>,
				      <0x10 0x7c709000 0x0 0x800>,
				      <0x10 0x7c700180 0x0 0x80>,
				      <0x10 0x7d511000 0x0 0x100>,
				      <0x10 0x7c720000 0x0 0x100>;
				reg-names = "hdmi", "dvp", "phy", "rm", "packet",
					    "metadata", "csc", "cec", "hd";
				/*
				 * audio (&dvp 1) + cec + reset (&dvp 2).
				 * primary hdmi/bvb also reference fixed-clocks.
				 */
				clocks = <&clk_hdmi_pixel>, <&clk_bvb>,
					 <&dvp 1>, <&clk_27MHz>;
				clock-names = "hdmi", "bvb", "audio", "cec";
				resets = <&dvp 2>;
				/*
				 * MAI DREQ number. This is BCM2712 *silicon-revision
				 * dependent*: the D0 stepping remaps it, and the firmware
				 * applies that remap itself by auto-loading
				 * overlays/bcm2712d0.dtbo on D0 boards. So the value baked
				 * into bcm2712-rpi-5-b.dtb (17) is the C0 value and is only
				 * ever seen before the fixup. We are a hand-written
				 * passthrough DT loaded by u-boot, so that overlay never
				 * reaches us -- carry the D0 value here.
				 *
				 * Measured on a Raspberry Pi 5 Model B Rev 1.1 (D0):
				 *   dtc bcm2712-rpi-5-b.dtb   hdmi1 dmas = <.. 0x41fa0011> (17)
				 *   /proc/device-tree runtime              0x41fa000d  (13)
				 *   dtc overlays/bcm2712d0.dtbo  fragment@7 -> 0x41fa000d
				 *
				 * Getting this wrong is silent: the DMA channel goes ACTIVE
				 * and then parks in DREQ_PAUSED forever, waiting on a DREQ
				 * nobody raises. The ALSA card, the PCM and the MAI all look
				 * healthy; only hw_ptr gives it away (frozen at 64 frames =
				 * the single 512-byte MAI FIFO fill that got through).
				 * Measured TI PER_MAP was 17 where bare metal used 13.
				 * A C0 board needs 17 here instead. This tree already commits to
				 * D0: TF-A is built with RPI5_PINCTRL_D0=1 (trusted-firmware-a_git.bb).
				 *
				 * 0x41fa000d = 13|(1<<30)|(1<<24)|(10<<16)|(15<<20)
				 *
				 * hdmi0 is left without dmas on purpose: only one DMA channel
				 * is exposed (see brcm,dma-channel-mask on &dma40), and the
				 * output DomA plays audio on is hdmi1 (HDMI-A-2).
				 */
				dmas = <&dma40 0x41fa000d>;
				dma-names = "audio-rx";
				/* list both downstream + upstream property names */
				ddc = <&ddc1>;
				ddc-i2c-bus = <&ddc1>;
				interrupt-parent = <&aon_intr>;
				interrupts = <11>, <12>, <13>, <14>, <15>;
				interrupt-names = "cec-tx", "cec-rx", "cec-low",
						  "hpd-connected", "hpd-removed";
				xen,path = "/soc@107c000000/hdmi@7c706400";
				xen,force-assign-without-iommu;
				/* Add the cec1 page 0x7d511000 (HDMI1 "cec" reg-name).
				 * hd (0x7c720000) is already mapped by hdmi0, so do not
				 * re-map it (avoid overlap -22). csc (0x7c700180) is in the
				 * clock's 0x7c700000 page. Matches domd.cfg iomem
				 * "0x107c706,3"+"0x107c709,1"+"0x107d511,1". */
				xen,reg = <0x10 0x7c706000 0x0 0x3000 0x10 0x7c706000>,
					  <0x10 0x7c709000 0x0 0x1000 0x10 0x7c709000>,
					  <0x10 0x7d511000 0x0 0x1000 0x10 0x7d511000>;
				status = "okay";
			};

			/* ===== MOP / MOPlet (Display Transposer / TXP for writeback) =====
			 * vc4_plane.c::vc4_plane_create_additional_planes() does:
			 *   drm_for_each_crtc(crtc, drm) {
			 *       if (vc4_crtc->feeds_txp) { txp_crtc = crtc; break; }
			 *   }
			 *   non_txp_crtc_mask = GENMASK(...) - drm_crtc_mask(txp_crtc);
			 *                                                    ^^^^^^^^^^
			 * If no TXP CRTC is found, txp_crtc is uninitialized (~= NULL) and
			 * drm_crtc_mask(NULL) dereferences NULL -> kernel OOPS. On BCM2712
			 * MOP/MOPlet take the TXP role, so adding both nodes fixes it.
			 *
			 * MOP/MOPlet are disp_intr child IRQs (sub-IRQ 1/0); their regs
			 * are on separate pages (0x107c500, 0x107c501) so iomem grants
			 * are needed.
			 */
			mop: mop@107c500000 {
				compatible = "brcm,bcm2712-mop";
				reg = <0x10 0x7c500000 0x0 0x28>;
				interrupt-parent = <&disp_intr>;
				interrupts = <1>;
				xen,path = "/soc@107c000000/mop@7c500000";
				xen,force-assign-without-iommu;
				xen,reg = <0x10 0x7c500000 0x0 0x1000 0x10 0x7c500000>;
				status = "okay";
			};

			moplet: moplet@107c501000 {
				compatible = "brcm,bcm2712-moplet";
				reg = <0x10 0x7c501000 0x0 0x20>;
				interrupt-parent = <&disp_intr>;
				interrupts = <0>;
				xen,path = "/soc@107c000000/moplet@7c501000";
				xen,force-assign-without-iommu;
				xen,reg = <0x10 0x7c501000 0x0 0x1000 0x10 0x7c501000>;
				status = "okay";
			};

			/* ===== PixelValve0 (HDMI output pixel stream) =====
			 * As a vc4-drm CRTC it receives the pixel stream from HVS and
			 * passes it to the HDMI encoder. If unplaced, Dom0 claims it and
			 * DomD vc4-drm cannot bind the PV and cannot take HDMI output
			 * control (a Dom0 framebuffer stays on HDMI). SPI 101 -> abs IRQ 133.
			 */
			pixelvalve0: pixelvalve@107c410000 {
				compatible = "brcm,bcm2712-pixelvalve0";
				reg = <0x10 0x7c410000 0x0 0x100>;
				interrupts = <0x0 0x65 0x4>;   /* GIC SPI 101 LEVEL_HIGH */
				interrupt-parent = <&gic>;
				xen,path = "/soc@107c000000/pixelvalve@7c410000";
				xen,force-assign-without-iommu;
				xen,reg = <0x10 0x7c410000 0x0 0x1000 0x10 0x7c410000>;
				status = "okay";
			};

			/* ===== PixelValve1 (HDMI output pixel stream, SPI 110 -> abs IRQ 142) ===== */
			pixelvalve1: pixelvalve@107c411000 {
				compatible = "brcm,bcm2712-pixelvalve1";
				reg = <0x10 0x7c411000 0x0 0x100>;
				interrupts = <0x0 0x6e 0x4>;   /* GIC SPI 110 LEVEL_HIGH */
				interrupt-parent = <&gic>;
				xen,path = "/soc@107c000000/pixelvalve@7c411000";
				xen,force-assign-without-iommu;
				xen,reg = <0x10 0x7c411000 0x0 0x1000 0x10 0x7c411000>;
				status = "okay";
			};

			/* =====================================================================
			 * RP1 / PCIe RC passthrough — ITERATION 1 (RC link-up scaffold)
			 *
			 * Goal: move USB (the touch panel) + Ethernet — which live inside RP1, a
			 * PCIe endpoint behind pcie2 — from Dom0 to DomD, toward the Zephyr-Dom0
			 * architecture where DomD owns the peripherals. USB+Eth share RP1's single
			 * PCIe RID / IOMMU stream and cannot be split, so the whole RC is passed.
			 *
			 * THIS ITERATION passes only the PCIe RC (pcie2) + its MSI controller
			 * (mip0). Validate on HW first: in DomD `lspci` should list the RP1
			 * endpoint and `dmesg | grep -i brcm-pcie` should show link-up. Only then
			 * add the RP1 sub-peripheral subtree (rp1_eth / rp1_usb0 / rp1_usb1 + the
			 * RP1 interrupt-controller + clocks) in iteration 2.
			 *
			 * KNOWN GAPS to resolve during HW iteration (NOT handled yet):
			 *   - resets: host pcie2 needs <&pcie_rescal>,<&bcm_reset 44>; omitted
			 *     here (the reset controllers are SoC-level, not in this partial DT),
			 *     so brcm-pcie may fail to bring the link up until they are added.
			 *   - clocks: pcie2 / RP1 clock providers are not in the partial DT.
			 *   - MSI: guest MSI via the BCM2712 MIP on Xen/ARM is UNPROVEN; the MIP
			 *     doorbell (0xff_fffff000) + the GIC SPI 128..191 lines must reach DomD
			 *     (the SPIs are intentionally not yet in domd.cfg irqs).
			 *   - Dom0 must release pcie2/rp1 (status=disabled in the Dom0 DT) and its
			 *     network must move onto a DomD netback vif (Stage 2).
			 * ===================================================================== */

			/* MSI controller for pcie2 (BCM2712 MIP0): maps 64 MSIs to GIC SPI
			 * 128..191 (EDGE_RISING). reg = control regs + the 4 KiB MSI doorbell. */
			mip0: msi-controller@1000130000 {
				compatible = "brcm,bcm2712-mip";
				reg = <0x10 0x00130000 0x00 0xc0>,
				      <0xff 0xfffff000 0x00 0x1000>;
				msi-controller;
				msi-ranges = <&gic 0x0 128 0x1 64>;   /* GIC_SPI 128, EDGE_RISING, x64 */
				brcm,msi-offset = <0>;
				xen,path = "/axi/msi-controller@1000130000";
				xen,force-assign-without-iommu;
				xen,reg = <0x10 0x00130000 0x0 0x1000 0x10 0x00130000>,
				          <0xff 0xfffff000 0x0 0x1000 0xff 0xfffff000>;
				status = "okay";
			};

			/* PCIe RC (pcie2): RP1 is its endpoint. reg/ranges/dma-ranges/
			 * interrupt-map are literal copies of bcm2712.dtsi pcie@1000120000.
			 * GIC_SPI 233(pcie)/234(msi); INTA-D = GIC_SPI 229..232. */
			pcie2: pcie@1000120000 {
				compatible = "brcm,bcm2712-pcie";
				reg = <0x10 0x00120000 0x00 0x9310>;
				device_type = "pci";
				linux,pci-domain = <2>;
				max-link-speed = <2>;
				num-lanes = <4>;
				#address-cells = <3>;
				#interrupt-cells = <1>;
				#size-cells = <2>;
				interrupt-parent = <&gic>;
				interrupts = <0x0 233 0x4>, <0x0 234 0x4>;   /* pcie, msi (LEVEL_HIGH) */
				interrupt-names = "pcie", "msi";
				interrupt-map-mask = <0x0 0x0 0x0 0x7>;
				interrupt-map = <0 0 0 1 &gic 0x0 229 0x4>,
						<0 0 0 2 &gic 0x0 230 0x4>,
						<0 0 0 3 &gic 0x0 231 0x4>,
						<0 0 0 4 &gic 0x0 232 0x4>;
				msi-controller;
				msi-parent = <&mip0>;
				/* RC bring-up needs the rescal + bridge resets. They are passed through as
				 * real-host-PA reset-controller nodes (defined at /passthrough level below);
				 * their xen,reg IS a correct literal host PA, so DomD brcm-pcie can reset the
				 * link. (0x2c = 44 = the bcm_reset "bridge" index, matching host DT.) */
				reset-names = "rescal", "bridge";
				resets = <&reset_controller119500>, <&reset_controller1504318 0x2c>;

				ranges =
					<0x02000000 0x00 0x00000000 0x1f 0x00000000 0x00 0x01000000>,
					<0x43000000 0x04 0x00000000 0x1c 0x00000000 0x03 0x00000000>;
				dma-ranges =
					<0x02000000 0x00 0x00000000 0x1f 0x00000000 0x00 0x00400000>,
					<0x43000000 0x10 0x00000000 0x00 0x00000000 0x10 0x00000000>,
					<0x03000000 0xff 0xfffff000 0x10 0x00130000 0x00 0x00001000>;

				xen,path = "/axi/pcie@1000120000";
				xen,force-assign-without-iommu;
				/* RC registers + a 16 MiB RP1 outbound MMIO window at host
				 * 0x1f_00000000. The pcie2 `ranges` 32-bit window above is trimmed to
				 * the SAME 16 MiB so the guest PCI core can only place RP1's BARs
				 * inside the mapped region: BAR1 (4 MiB peripheral window: eth@100000,
				 * usb0@200000, usb1@300000=touch) is the largest BAR so it lands at
				 * bus 0x0 -> host 0x1f_00000000, and BAR0 (the MSI-X table) lands just
				 * above it. Without this trim the guest assigns the MSI-X-table BAR
				 * somewhere in the full 4 GiB window that is NOT p2m-mapped, and
				 * rp1_probe's pci_alloc_irq_vectors(PCI_IRQ_MSIX) faults (DABT FSC=0,
				 * address-size) reading the table. (Xen ARM has no vPCI/MSI-X
				 * emulation -- has_vpci()==false -- so the guest reads the real table
				 * and programs the real BCM2712 MIP directly.) */
				xen,reg = <0x10 0x00120000 0x0 0xa000 0x10 0x00120000>,
				          <0x1f 0x00000000 0x0 0x01000000 0x1f 0x00000000>;
				status = "okay";

				/* ===== RP1 subtree (DESCRIPTIVE only) ==================================
				 * Xen dom0less-build.c handle_passthrough_prop() maps xen,reg pbase as a
				 * LITERAL host PA with NO ranges translation, so a per-device xen,reg using
				 * the RP1-internal 0xc0_40.. address would map a bogus host PA. The real RP1
				 * MMIO is mapped ONCE via the pcie2 xen,reg aperture (host 0x1f_00000000)
				 * above. These nodes carry NO xen,path/xen,reg; they exist only so DomD's
				 * kernel binds rp1/macb/dwc3 drivers, with reg in RP1-internal space that
				 * the ranges below translate. RP1 device IRQs are internal to RP1's own
				 * irqchip (this node); only the upstream MSIs reach the GIC (SPI 160..223,
				 * granted via domd.cfg irqs). ===================================== */
				rp1: rp1@c040000000 {
					compatible = "simple-bus";
					#address-cells = <0x2>;
					#size-cells = <0x2>;
					#interrupt-cells = <0x2>;
					interrupt-controller;
					interrupt-parent = <&rp1>;
					ranges = <0xc0 0x40000000 0x02000000 0x0 0x0 0x0 0x00410000>;
					dma-ranges = <0x10 0x00000000 0x43000000 0x10 0x00000000 0x10 0x00000000>,
					             <0xc0 0x40000000 0x02000000 0x0 0x00000000 0x0 0x00410000>,
					             <0x00 0x00000000 0x02000000 0x10 0x00000000 0x10 0x00000000>;

					/* RP1 Gigabit Ethernet (Eth -> DomD, toward Zephyr-Dom0). */
					ethernet@c040100000 {
						compatible = "cdns,macb";
						#address-cells = <0x1>;
						#size-cells = <0x0>;
						reg = <0xc0 0x40100000 0x0 0x4000>;
						interrupts = <0x6 0x4>;
						phy-mode = "rgmii-id";
						phy-handle = <&eth_phy>;
						phy-reset-gpios = <&gpiod0000 0x20 0x1>;
						phy-reset-duration = <0x5>;
						/*
						 * A locally-administered, DETERMINISTIC MAC.
						 * All-zero is not a valid Ethernet address:
						 * macb_main.c (macb_probe -> of_get_mac_address)
						 * rejects it, there is no nvmem cell, and
						 * macb falls back to "invalid hw address,
						 * using random" -- a different MAC on every
						 * boot. The board's real MAC cannot be put
						 * here: the firmware patches it into the HOST
						 * device tree, which DomD never sees. So: a
						 * fixed value with the locally-administered
						 * bit (0x02), no OUI, "DOMD" in the middle;
						 * the last octet differs from the Pi 4
						 * layer's (01) so the two boards never share
						 * one. Fixed means two of these boards on one
						 * L2 segment would collide -- change the last
						 * octet per board if that ever happens.
						 */
						local-mac-address = [02 44 4f 4d 44 05];
						clock-names = "pclk", "hclk", "tsu_clk";
						clocks = <&macb_pclk>, <&macb_hclk>, <&clocks18000 0x1d>;
						status = "okay";

						eth_phy: ethernet-phy@1 {
							reg = <0x1>;
							brcm,powerdown-enable;
						};
					};

					/* RP1 USB0 (dwc3 host). */
					usb@c040200000 {
						compatible = "snps,dwc3";
						reg = <0xc0 0x40200000 0x0 0x100000>;
						interrupts = <0x1f 0x1>;
						dr_mode = "host";
						usb3-lpm-capable;
						status = "okay";
					};

					/* RP1 USB1 (dwc3 host) = HDMI-A-2 USB touch panel. */
					usb@c040300000 {
						compatible = "snps,dwc3";
						reg = <0xc0 0x40300000 0x0 0x100000>;
						interrupts = <0x24 0x1>;
						dr_mode = "host";
						usb3-lpm-capable;
						status = "okay";
					};

					/* RP1 GPIO (eth phy-reset-gpios references this). */
					gpiod0000: gpio@c0400d0000 {
						compatible = "raspberrypi,rp1-gpio";
						#gpio-cells = <0x2>;
						gpio-controller;
						#interrupt-cells = <0x2>;
						interrupt-controller;
						reg = <0xc0 0x400d0000 0x0 0xc000 0xc0 0x400e0000 0x0 0xc000 0xc0 0x400f0000 0x0 0xc000>;
						interrupts = <0x0 0x4 0x1 0x4 0x2 0x4>;
						gpio-ranges = <&gpiod0000 0x0 0x0 0x36>;
						status = "okay";
						/* GPIO45 -> pwm1 (FAN). Copy of rp1.dtsi:918 rp1_pwm1_gpio45. */
						rp1_pwm1_gpio45: rp1_pwm1_gpio45 {
							function = "pwm1";
							pins = "gpio45";
							bias-pull-down;
						};
					};

					/* RP1 clock controller (macb tsu_clk = index 0x1d). */
					clocks18000: clocks@c040018000 {
						compatible = "raspberrypi,rp1-clocks";
						#clock-cells = <0x1>;
						reg = <0xc0 0x40018000 0x0 0x10038>;
						clocks = <&clk_xosc>;
						status = "okay";
					};

					/* RP1 PWM1 = FAN driver. rp1.dtsi:407 pwm@9c000. pwm-rp1 exposes a
					 * 4-channel pwmchip. The GPIO45->pwm1 mux references rp1_pwm1_gpio45
					 * inside gpiod0000. The FAN (pwm1 ch3) is auto-controlled the native way
					 * by the kernel thermal-zone (cpu_thermal) + cooling_fan (pwm-fan) (see the
					 * thermal block directly under /passthrough; daemon removed). */
					rp1_pwm1: pwm@c04009c000 {
						compatible = "raspberrypi,rp1-pwm";
						reg = <0xc0 0x4009c000 0x0 0x100>;
						#pwm-cells = <0x3>;
						clocks = <&clocks18000 0x12>;
						assigned-clocks = <&clocks18000 0x12>;
						assigned-clock-rates = <50000000>;
						pinctrl-names = "default";
						pinctrl-0 = <&rp1_pwm1_gpio45>;
						status = "okay";
					};
				};
			};
		};

		/* ===== Bluetooth: uarta + the gio bank that carries BT_ON =====
		 * BCM2712 gives Bluetooth its own UART, which is why this is so much
		 * smaller than the RPi4 equivalent. Three separate paths exist on this
		 * SoC and none of them contend:
		 *   Xen console  uart10 = pl011 @0x7d001000, SPI 121 (SPI 120 on D0),
		 *                dedicated pins, no pinctrl property at all
		 *   Bluetooth    uarta  = brcm,bcm7271-uart @0x7d50c000, SPI 276
		 *   40-pin hdr   RP1's serial@30000.. behind PCIe (another chip)
		 * On BCM2711 only uart0/uart1 can reach either the header or the BT
		 * module, so giving BT the fast pl011 forces the console onto the mini
		 * UART and drags in force_turbo. None of that applies here.
		 *
		 * The zephyr flavour's boot.cmd marks both host nodes xen,passthrough.
		 * For DOM0_OS=linux uart_bt is stripped instead; see the note at the node.
		 *
		 * DIFFERENCES FROM THE RPi4 NODE, all in our favour:
		 *   - clock-frequency is declared directly (96 MHz), exactly as the host
		 *     DT declares it, so there is no cprman dependency and no
		 *     fixed-clock substitute whose rate has to be measured first.
		 *   - 0x7d50c000 is a page of its own; nothing else in the host DT sits
		 *     in it and SPI 276 is declared by this node alone. So no page
		 *     neighbours to `fdt rm` and no shared-SPI argument to make.
		 *   - NO /aliases ENTRY IS NEEDED. On RPi4 the physical UART and Xen's
		 *     emulated vpl011 are both pl011s driven by amba-pl011.c out of one
		 *     amba_ports[] array, so serial1 = &uart0 was required to keep
		 *     ttyAMA0 for the vpl011. Here the BT UART is 8250-family
		 *     (8250_bcm7271.c -> serial8250_register_8250_port) and lands in the
		 *     ttyS pool, while the vpl011 keeps ttyAMA0 from amba-pl011.c. The
		 *     two pools are independent.
		 *
		 * BUT ONE RPi4 LESSON DOES CARRY OVER: because this is an 8250-family
		 * port, DomD's bootargs need 8250.nr_uarts=1. bcm2712_defconfig sets
		 * CONFIG_SERIAL_8250_RUNTIME_UARTS=0, so nr_uarts starts at zero and
		 * serial8250_register_8250_port() finds no free port. The host DT carries
		 * 8250.nr_uarts=1 in /chosen/bootargs, but DomD does not inherit that --
		 * boot.cmd sets DomD's bootargs explicitly. It is added there, in the
		 * zephyr flavour's boot.cmd; the linux flavour strips the UART and needs
		 * none.
		 *
		 * pinctrl IS wired, through SCMI. The host node points at
		 * &uarta_24_pins and &bt_shutdown_pins under pinctrl@7d504100, which
		 * DomD does not drive directly (see the SCMI node below). GPIO24-27 are
		 * muxed to f_uart0 by scmi_uarta_24_pins in the SCMI node; BT_ON (gio
		 * line 29) is already function f_gpio at reset, so bt_shutdown_pins
		 * needs no SCMI group and shutdown-gpios below is enough.
		 */
		/* SODEV-LINUX-DOM0-SD-STRIP-BEGIN: the Bluetooth UART. domd-vc4.bb
		 * strips it for DOM0_OS=linux. That flavour sets up no SCMI (see its
		 * boot.cmd), so GPIO24-27 are never muxed to the UART and Bluetooth
		 * cannot work there; and its boot.cmd does not mark the host node
		 * xen,passthrough, so Xen gives the node and SPI 276 to the Linux Dom0
		 * and a DomD that claimed them as well would fail to be created
		 * (-EBUSY). Nothing outside this block refers to uart_bt or to its
		 * bluetooth child. */
		uart_bt: serial@107d50c000 {
			compatible = "brcm,bcm7271-uart";
			reg = <0x10 0x7d50c000 0x0 0x1000>;	/* page-rounded from 0x20 */
			reg-names = "uart";
			reg-shift = <0x02>;
			reg-io-width = <0x04>;
			interrupts = <0x00 0x114 0x04>;		/* GIC SPI 276, this node only */
			interrupt-parent = <&gic>;
			clock-frequency = <96000000>;
			uart-has-rtscts;
			auto-flow-control;
			skip-init;
			pinctrl-names = "default";
			pinctrl-0 = <&scmi_uarta_24_pins>;
			xen,path = "/soc@107c000000/serial@7d50c000";
			xen,force-assign-without-iommu;
			xen,reg = <0x10 0x7d50c000 0x0 0x1000 0x10 0x7d50c000>;
			status = "okay";

			bluetooth {
				compatible = "brcm,bcm43438-bt";
				max-speed = <3000000>;
				shutdown-gpios = <&gio 29 0>;	/* BT_ON */
				/* The host node has local-bd-address but NOT
				 * fallback-bd-address (RPi4's has both); this node has
				 * it as the RPi4 node does. It only decides whether
				 * local-bd-address is read (hci_dev_setup_sync()),
				 * and this node carries no local-bd-address, so here
				 * it changes nothing. */
				fallback-bd-address;
				/* sco-routing = 1 (Transport = HCI) so SCO does not go to
				 * the chip's PCM pins, which this guest does not have.
				 * hci_bcm.c sends it during bcm_setup() as HCI opcode
				 * 0xfc1c; byte order per the brcm,bluetooth.yaml binding.
				 * Needed for HFP, harmless for A2DP. */
				brcm,bt-pcm-int-params = [01 02 00 01 01];
				/* vbat / vddio. hci_bcm.c's bcm_get_resources() takes both with
				 * devm_regulator_get(), not the _optional variant, so they are
				 * mandatory. A plain Raspberry Pi DT does not declare them either,
				 * but there the regulator core inserts dummy supplies and the probe
				 * succeeds. In a dom0less guest that is refused:
				 *   "incomplete constraints, dummy supplies not allowed (id=vbat)"
				 *   -> "error -ENODEV: Failed to get supply 'vbat'"   (measured on
				 *      the Pi 4, which hit this first)
				 *
				 * The mechanism, from primary sources, and it has nothing to do with
				 * how many regulators the DT declares:
				 *   include/linux/of.h        of_have_populated_dt() is just
				 *                             of_property_present(of_root, "compatible")
				 *   drivers/regulator/core.c  if (of_have_populated_dt())
				 *                                     has_full_constraints = true;
				 * A dom0less guest DT's root carries only #address-cells and
				 * #size-cells and no compatible -- confirmed by decompiling a DTB
				 * recovered from the board -- so has_full_constraints is permanently
				 * false and dummy supplies stay forbidden.
				 *
				 * Hence the explicit supply. What it points at is an always-on fixed
				 * regulator with no GPIO, i.e. it switches nothing: the CYW43455 is
				 * powered from the board unconditionally. It exists to satisfy
				 * hci_bcm's requirement, and it is defined next to wl_on_reg below,
				 * OUTSIDE the SD-strip region -- see the note on that node for what
				 * happens if it is not.
				 */
				vbat-supply = <&bt_vbat_reg>;
				vddio-supply = <&bt_vbat_reg>;
				status = "okay";
			};
		};
		/* SODEV-LINUX-DOM0-SD-STRIP-END */

		/* SODEV-LINUX-DOM0-SD-STRIP-BEGIN: domd-vc4.bb strips everything from here to
		 * the matching end marker below wl_on_reg for DOM0_OS=linux:
		 * gio, the SCMI shared memory and protocol nodes with their pin
		 * groups, the Wi-Fi SDIO controller and wl_on_reg. That flavour
		 * applies no SCMI host overlay, so there is no SCMI server for
		 * these nodes to reach, the Wi-Fi pins cannot be muxed and the
		 * shared-memory page is not set aside. The Wi-Fi SDIO
		 * controller stays with the Linux Dom0, which also takes its
		 * interrupt (SPI 274): a DomD that claimed it too would make
		 * Xen panic at DomD creation (route_irq_to_guest -EBUSY).
		 * Nothing that survives the strip may refer to a label inside it: the
		 * Bluetooth UART's block above, stripped in the same flavour, is the
		 * one user outside it (&gio, &scmi_uarta_24_pins). */
		/* gio: the 32+4-bit GPIO bank at 0x7d508500. BT_ON is line 29
		 * (gpio-line-names index 29 in the host DT), and the bluetooth node
		 * above drives it through shutdown-gpios.
		 *
		 * A PLAIN NODE ON PURPOSE -- no xen,path, no xen,reg, no
		 * xen,force-assign-without-iommu. Its MMIO page (0x7d508000) is already
		 * mapped by ddc0 above, and every host page must be mapped exactly once
		 * across this partial DT. dom0less also requires xen,reg on any node
		 * that HAS xen,path (dom0less-build.c:481), so the two must be dropped
		 * together. Exactly the ddc1 situation, handled the same way. The host
		 * side is released by boot.cmd's `fdt set ... gpio@7d508500
		 * xen,passthrough`.
		 *
		 * interrupts are omitted: the host node's interrupt-parent is the L2
		 * intc at 0x7d508400, not the GIC, so Xen routes nothing, and
		 * shutdown-gpios only needs an output.
		 *
		 * SHARED WITH WI-FI. WL_ON is line 28 and BT_ON is line 29 on this same
		 * controller, so this is ONE node with two users: the bluetooth child of
		 * serial@107d50c000 above (shutdown-gpios, line 29) and wl_on_reg below
		 * (line 28). The former bcm2712-raspberrypi5-wifi.dtso declared a second
		 * gpio@107d508500 of its own; that duplicate is NOT carried over -- the
		 * dtso content was merged into this file instead of being applied as an
		 * overlay (the partial DT is compiled without dtc -@, so it has no
		 * __symbols__ and no overlay can target &passthrough).
		 *
		 * gpio-line-names is copied from the host DTB. It is documentation only
		 * -- nothing resolves a line by name here -- but it is what lets a reader
		 * check line 28/29 without going back to the host tree.
		 */
		gio: gpio@107d508500 {
			compatible = "brcm,brcmstb-gpio";
			reg = <0x10 0x7d508500 0x0 0x40>;
			gpio-controller;
			#gpio-cells = <0x02>;
			brcm,gpio-direct;
			brcm,gpio-bank-widths = <32 4>;
			gpio-line-names =
				"",                 /*  0 */
				"2712_BOOT_CS_N",   /*  1 */
				"2712_BOOT_MISO",   /*  2 */
				"2712_BOOT_MOSI",   /*  3 */
				"2712_BOOT_SCLK",   /*  4 */
				"", "", "", "", "", "", "", "",     /*  5-12 */
				"",                 /* 13 */
				"PCIE_SDA",         /* 14 */
				"PCIE_SCL",         /* 15 */
				"", "",             /* 16-17 */
				"-", "-",           /* 18-19 */
				"PWR_GPIO",         /* 20 */
				"2712_G21_FS",      /* 21 */
				"-", "-",           /* 22-23 */
				"BT_RTS",           /* 24 */
				"BT_CTS",           /* 25 */
				"BT_TXD",           /* 26 */
				"BT_RXD",           /* 27 */
				"WL_ON",            /* 28 <- wl_on_reg */
				"BT_ON",            /* 29 <- bluetooth shutdown-gpios */
				"WIFI_SDIO_CLK",    /* 30 */
				"WIFI_SDIO_CMD",    /* 31 */
				"WIFI_SDIO_D0",     /* 32 */
				"WIFI_SDIO_D1",     /* 33 */
				"WIFI_SDIO_D2",     /* 34 */
				"WIFI_SDIO_D3";     /* 35 */
		};

		/* ===== SCMI: how DomD muxes its pins on the pin controller =====
		 *
		 * pinctrl@7d504100 (the pin controller that muxes these pins and sets their
		 * pulls) is not given to DomD. Measured, twice: putting the node in this
		 * partial DT with the C0 compatible (brcm,bcm2712c0-pinctrl) panics DomD
		 * with an Asynchronous SError Interrupt inside brcmstb_pull_config_set(), and
		 * reading a pad register (0x107d504124) from the U-Boot prompt SErrors the
		 * same way. A blind `mw.l` premux from boot.cmd left the console dead. Both
		 * SErrors are C0 pad offsets past the end of the 0x20 D0 block (see the
		 * TF-A D0 patch), so the in-tree route is SCMI: DomD asks EL3 to do the mux.
		 *
		 * The server is TF-A's (xen-troops fork, plat/rpi/rpi5/scmi/* plus
		 * drivers/scmi-msg/scmi_pinctrl.c, protocol 0x19). It is compiled in by
		 * SCMI_SERVER_SUPPORT=1, which the xt-prod-devel-rpi5-domd bbappend ties to
		 * MACHINE_FEATURES += "scmi" -- the same switch that pulls scmi-config.cfg
		 * (CONFIG_ARM_SCMI_PROTOCOL / CONFIG_PINCTRL_SCMI) into this kernel.
		 *
		 * Why DomD may drive it at all, and why no permission handshake appears
		 * here: Xen 4.22's mediator (xen/arch/arm/firmware/scmi-smc.c)
		 * forwards exactly ONE SMC function ID -- the host DT's arm,smc-id -- and
		 * only from the single domain that has xen,sci_type = "scmi_smc". boot.cmd
		 * puts that on /chosen/domD and adds `scmi-smc-passthrough` to the
		 * hypervisor command line (without it scmi_smc_domain_init() returns
		 * -EINVAL for a non-hardware domain and DomD is never created). TF-A maps
		 * 0x82000002 to agent 0 (plat/rpi/rpi5/rpi5_svc_setup.c), and
		 * plat_scmi_pinctrl_{pin,group}_permitted() in scmi_policy.c return true
		 * unconditionally for agent 0. So DomD is agent 0 and every pin is already
		 * permitted; scmi_policy.c needs no change, and neither the
		 * `access-controllers` binding nor the EPAM multi-agent
		 * `epam,secondary-agents` extension (absent from upstream Xen) is used.
		 *
		 * protocol@16 (reset) is deliberately NOT declared: nothing in this guest
		 * consumes it -- pciex takes its resets from reset_controller119500, which
		 * is proven on this board -- and an unused protocol is one more thing that
		 * can fail at probe.
		 */
		scmi_shm0: scmi_shm@3ff00000 {
			compatible = "arm,scmi-shmem";
			reg = <0x00 0x3ff00000 0x00 0x1000>;
			/*
			 * Agent 0's channel. Base and layout are TF-A's, not ours:
			 * plat/rpi/rpi5/platform.mk sets RPI_SCMI_SHMEM_BASE := 0x3ff00000
			 * and scmi.c places agent n at base + n * PAGE_SIZE. The host DT
			 * overlay (bcm2712-raspberrypi5-scmi-host.dtso) reserves the whole
			 * 64 KiB window; only this one page is mapped here.
			 *
			 * xen,reg WITHOUT xen,path is legal and intentional: dom0less-build.c
			 * requires xen,reg whenever xen,path is present, but accepts xen,reg
			 * alone when xen,force-assign-without-iommu is set (handle_prop_pfdt(),
			 * and handle_passthrough_prop() returns 0 early for a NULL path). That
			 * is what we want -- this is a RAM carve-out with no interrupts and no
			 * IOMMU stream ID, so there is nothing for xen,path to resolve.
			 * Mapped 1:1 (DomD is direct-mapped), as p2m_mmio_direct_dev, which
			 * matches the devm_ioremap() the arm,scmi-shmem consumer does.
			 */
			xen,force-assign-without-iommu;
			xen,reg = <0x00 0x3ff00000 0x00 0x1000 0x00 0x3ff00000>;
		};

		scmi: scmi {
			compatible = "arm,scmi-smc";
			/* = RPI5_SIP_SMC_SCMI (plat/rpi/rpi5/include/rpi5_smc.h). Xen matches
			 * this against the host DT's arm,smc-id and forwards only that fid. */
			arm,smc-id = <0x82000002>;
			#address-cells = <0x01>;
			#size-cells = <0x00>;
			shmem = <&scmi_shm0>;

			scmi_pinctrl: protocol@19 {
				reg = <0x19>;
				#pinctrl-cells = <0x00>;

				/*
				 * Group names and contents mirror pinctrl@7d504100's
				 * sdio2_30_pins / uarta_24_pins in the shipped
				 * bcm2712-rpi-5-b.dtb, with one difference: the function
				 * strings carry the f_ prefix. The native
				 * brcm,bcm2712c0-pinctrl driver calls them "sd2"/"uart0";
				 * TF-A's SCMI server builds its names with FUNC(f) =
				 * "f_" #f (bcm2712_pinctrl.c), so over SCMI they are
				 * "f_sd2"/"f_uart0".
				 *
				 * The nested pin_* subnode form is what
				 * pinconf_generic_dt_node_to_map_all() wants (pinctrl-scmi
				 * sets it as .dt_node_to_map): it maps the group node AND
				 * each child. `pins` + `function` yields a mux map keyed by
				 * the pin name, which resolves because TF-A exposes a 1:1
				 * pin-to-group mapping with identical names (see the comment
				 * in plat_scmi_pinctrl_group_permitted()). The former
				 * bcm2712-raspberrypi5-domd-scmi.dtso (EPAM's, since removed)
				 * left these groups EMPTY and relied on a Linux Dom0 having
				 * applied the host
				 * DT's copy; this board's Dom0 is Zephyr, so the settings
				 * have to be here or nothing is muxed at all.
				 *
				 * bias-* IS written here, which is safe only with TF-A's D0 tables.
				 * Both the mux and the pad registers of this block moved between
				 * BCM2712 steppings, and the xen-troops TF-A this build fetches
				 * carries only the C0 map: on this D0 board it aims the pull writes
				 * for these pins at offset 0x24, four bytes past the end of the 0x20
				 * window the firmware's bcm2712d0.dtbo declares. That
				 * is an unrecoverable abort in EL3 -- release builds have
				 * CRASH_REPORTING=0 -- so the CPU that issued the request simply never
				 * came back: RCU reported a stall on it, the IPI from the other CPU was
				 * never taken, and because the console is synchronous the whole board
				 * went silent. meta-xt-rpi5's
				 * 0001-plat-rpi5-pinctrl-add-BCM2712-D0-stepping-tables.patch adds the
				 * D0 map (pads land at 0x14/0x18) and RPI5_PINCTRL_D0=1 selects it.
				 *
				 * The pulls are not optional. Measured on this board, mux-only vs
				 * mux+pulls, with everything else identical:
				 *   mux only : brcmfmac: F1 signature read @0x18000000=0xffffffff
				 *              brcmf_chip_recognition: MMIO read failed -> probe -52
				 *   mux+pulls: brcmfmac: F1 signature read @0x18000000=0x15264345
				 *              using brcm/brcmfmac43455-sdio for chip BCM4345/6
				 * i.e. without the pull-ups on CMD and DAT0-3 the card answers CMD5 but
				 * every backplane read comes back all-ones.
				 */
				scmi_sdio2_30_pins: scmi_sdio2_30_pins {
					pin_clk {
						function = "f_sd2";
						pins = "gpio30";
						bias-disable;
					};
					pin_cmd {
						function = "f_sd2";
						pins = "gpio31";
						bias-pull-up;
					};
					pins_dat {
						function = "f_sd2";
						pins = "gpio32", "gpio33", "gpio34", "gpio35";
						bias-pull-up;
					};
				};

				scmi_uarta_24_pins: scmi_uarta_24_pins {
					pin_rts {
						function = "f_uart0";
						pins = "gpio24";
						bias-disable;
					};
					pin_cts {
						function = "f_uart0";
						pins = "gpio25";
						bias-pull-up;
					};
					pin_txd {
						function = "f_uart0";
						pins = "gpio26";
						bias-disable;
					};
					pin_rxd {
						function = "f_uart0";
						pins = "gpio27";
						bias-pull-up;
					};
				};

			};
		};

		/* ===== Wi-Fi: SDIO controller + WL_ON regulator -> DomD =====
		 * Merged from the former meta-xt-driver-domain/recipes-kernel/linux/files/
		 * bcm2712-raspberrypi5-wifi.dtso (since removed) rather than applied as an
		 * overlay. Two
		 * reasons: the partial DT is compiled without `dtc -@` (on BOTH boards,
		 * so this is not an rpi5 gap to fix) and therefore carries no
		 * __symbols__ for &passthrough to bind to; and the dtso's own
		 * gpio@107d508500 / clk_emmc2 would collide with the nodes this file
		 * already has. Merging resolves both by construction. The dtso also had
		 * an unresolved apply-order dependency on scmi_sdio2_30_pins, which
		 * disappears here.
		 *
		 * Radio: BCM43455 (same part as RPi4 -- rpm -qlp
		 * linux-firmware-rpidistro-bcm43455 ships
		 * brcmfmac43455-sdio.raspberrypi,5-model-b.bin), driven by brcmfmac over
		 * SDIO. This is a DIFFERENT controller from the SD card
		 * (mmc@1000fff000): SPI 274 vs SPI 273, and separate MMIO.
		 * Unlike RPi4 -- where mmcnr and emmc2 share SPI 126 -- there
		 * is no interrupt to arbitrate here. The block is stripped for
		 * DOM0_OS=linux all the same, because that flavour has no SCMI
		 * to mux the SDIO pins (see the marker above gio).
		 *
		 * pinctrl IS wired, through SCMI. GPIO30-35 must be muxed to
		 * f_sd2 or the controller sees no card: left to the VideoCore
		 * firmware, on the assumption that it pre-muxes them before Xen
		 * starts, the radio did not enumerate. scmi_sdio2_30_pins above
		 * makes DomD do the mux itself via EL3.
		 *
		 * xen,reg maps 0x1100000 page-rounded. The host reg is two windows
		 * (host @0x1100000 len 0x260, cfg @0x1100400 len 0x200); both fall in
		 * the single 4 KiB page, and no other node in this file maps it. BOTH
		 * windows are required: sdhci-brcmstb keeps its vendor registers in the
		 * "cfg" window (priv->cfg_regs), so dropping it would break probe.
		 * boot.cmd releases the host side with
		 *   fdt set /axi/mmc@1100000 xen,passthrough
		 * (the gio half of the former wifi-passthrough.dtso is already done for BT).
		 *
		 * ===== DMA: ADMA2 IS ENABLED HERE, DELIBERATELY =====
		 * This is the one DMA-capable passthrough path in the Wi-Fi/BT set, and
		 * it works for a reason specific to BCM2712. Traced end to end:
		 *
		 *  - sdhci-brcmstb.c:693 calls sdhci_read_caps(), i.e. the REAL hardware
		 *    capabilities register at offset 0x40 is read. Nothing in the 2712
		 *    path substitutes hardcoded caps.
		 *  - sdhci-brcmstb.c:694-695 clears SDHCI_CAN_64BIT only when the match
		 *    data sets BRCMSTB_MATCH_FLAGS_NO_64BIT. match_priv_2712.flags is
		 *    BRCMSTB_MATCH_FLAGS_USE_CARD_BUSY alone, so 64-bit ADMA survives.
		 *  - The host DT's sdhci-caps-mask = <0xc000 0x00> does NOT touch DMA.
		 *    __sdhci_read_caps() reads that property as a u64
		 *    (sdhci.c:4181-4184), so <0xc000 0x00> is 0x0000c000_00000000:
		 *    lower_32_bits() = 0 leaves caps(0x40) -- and therefore
		 *    SDHCI_CAN_DO_ADMA2 (bit 19, 0x00080000) and SDHCI_CAN_DO_SDMA
		 *    (bit 22, 0x00400000) -- completely untouched. upper_32_bits() =
		 *    0xc000 masks caps1 bits 14-15 = SDHCI_RETUNING_MODE_MASK, which is
		 *    a tuning concern, not a DMA one. The mask is carried over verbatim.
		 *  - No external DMA controller is involved, so unlike RPi4 there is
		 *    nothing extra to pass through. See the contrast note below.
		 *
		 * WHY THIS IS SAFE WITHOUT AN IOMMU. xen,force-assign-without-iommu
		 * means the controller's bus-master writes land at GUEST physical
		 * addresses. DomD is direct-mapped in dom0less, so guest PA == host PA
		 * and the descriptors are valid. /axi's dma-ranges on the host is an
		 * identity map for the low 64 GiB anyway (measured), so moving the node
		 * under /passthrough (which has no dma-ranges) changes no translation.
		 * ==> DomD's direct-map is a PRECONDITION for Wi-Fi DMA. Removing it
		 * would not disable DMA, it would corrupt memory silently.
		 *
		 * CONTRAST WITH RPI4. RPi4's Wi-Fi SDIO is mmcnr@7e300000, an
		 * Arasan block with no usable internal bus master: bound as
		 * brcm,bcm2835-sdhci (sdhci-iproc.c's bcm2835_data sets .caps
		 * without ADMA2 or SDMA and .missing_caps = true, so the
		 * capabilities register is never read) it is PIO by driver
		 * design. DomD binds it with the downstream bcm2835-mmc.c
		 * instead, which does DMA through an EXTERNAL engine,
		 * dma-controller@7e007000, passed to DomD alongside it. This
		 * controller has ADMA2 built in, so nothing extra is passed
		 * through.
		 * RPi4's SD CARD is a different controller and a different story: emmc2
		 * is brcm,bcm2711-emmc2 -> bcm2711_data, which sets no caps override at
		 * all, so it reads real hardware caps and ADMA2 works. That path is
		 * already enabled in the RPi4 partial DT.
		 *
		 * IF ADMA MISBEHAVES ON THIS BOARD, the escape hatch is a DT property,
		 * not a code change -- but MIND THE EXISTING VALUE. This node already
		 * carries sdhci-caps-mask = <0xc000 0x00> (inherited from the host, for
		 * the retuning bits), and a DT property is single-valued, so the ADMA
		 * bits have to be COMBINED into it, not written over it:
		 *
		 *     sdhci-caps-mask = <0xc000 0x00480000>;
		 *       upper 32 bits 0xc000     -> caps1 bits 14-15, retuning (KEEP)
		 *       lower 32 bits 0x00480000 -> caps(0x40): SDHCI_CAN_DO_ADMA2
		 *                                   (bit 19) | SDHCI_CAN_DO_SDMA (bit 22)
		 *
		 * Writing the bare <0x0 0x00480000> here would silently drop the
		 * retuning mask. <0x0 0x00480000> is the correct form only for RPi4's
		 * emmc2, which has no pre-existing mask. That is the same property and
		 * the same ADMA bits that were needed for RPi4's emmc2 with one
		 * particular SD card (SanDisk 512 GiB SDXC ST512, manfid 0x03: ADMA
		 * failed every transfer with "mmc0: ADMA error: 0x02000000" -> error -5
		 * -> infinite retry, and DomD hung in rootwait). That was judged
		 * media/individual dependent and deliberately kept OUT of the source
		 * tree. Do NOT add the
		 * mask pre-emptively here. Wi-Fi is not on the rootfs path, so a failure
		 * here degrades the radio rather than hanging the boot -- check
		 * `dmesg | grep -iE "mmc.*(ADMA|SDMA|PIO)"` on the board and only then
		 * decide.
		 */
		sdio2: mmc@1001100000 {
			#address-cells = <0x01>;
			#size-cells = <0x00>;
			compatible = "brcm,bcm2712-sdhci";
			reg = <0x10 0x1100000 0x00 0x260 0x10 0x1100400 0x00 0x200>;
			reg-names = "host", "cfg";
			interrupts = <0x00 0x112 0x04>;		/* GIC SPI 274 */
			interrupt-parent = <&gic>;
			clocks = <&clk_emmc2>;
			sdhci-caps-mask = <0xc000 0x00>;
			sdhci-caps = <0x00 0x00>;
			supports-cqe;
			mmc-ddr-3_3v;
			bus-width = <0x04>;
			vmmc-supply = <&wl_on_reg>;
			sd-uhs-ddr50;
			non-removable;
			pinctrl-names = "default";
			pinctrl-0 = <&scmi_sdio2_30_pins>;
			xen,path = "/axi/mmc@1100000";
			xen,force-assign-without-iommu;
			xen,reg = <0x10 0x1100000 0x00 0x1000 0x10 0x1100000>;
			status = "okay";

			wifi@1 {
				reg = <0x01>;
				compatible = "brcm,bcm4329-fmac";
				/*
				 * WITHOUT THIS brcmfmac NEVER FINDS ITS FIRMWARE. The driver builds
				 * the firmware filename from the board type, and in a dom0less guest
				 * there is nothing to derive it from: brcmf_of_probe() reads
				 * brcm,board-type from this node and otherwise falls back to the DT
				 * root compatible -- which a partial DT does not have (that same
				 * missing root compatible is why of_have_populated_dt() is false here
				 * and the regulator core refuses dummy supplies). So it asked for the
				 * generic brcm/brcmfmac43455-sdio.bin, which linux-firmware does not
				 * ship: only per-board names exist. Measured, once the SCMI pinmux
				 * made the chip reachable at all:
				 *   brcmfmac: F1 signature read @0x18000000=0x15264345   <- chip OK
				 *   brcmfmac: using brcm/brcmfmac43455-sdio for chip BCM4345/6
				 *   Direct firmware load for brcm/brcmfmac43455-sdio.bin failed -2
				 * The three files that DO exist on the rootfs are
				 * brcmfmac43455-sdio.raspberrypi,5-model-b.{bin,txt,clm_blob}, which is
				 * exactly the string below.
				 */
				brcm,board-type = "raspberrypi,5-model-b";
				local-mac-address = [00 00 00 00 00 00];
			};
		};

		/* WL_ON: powers the radio. gio line 28. The 25 ms startup delay is the
		 * dtso's value (0x249f0 us) -- brcmfmac probes the SDIO card right after
		 * the regulator enables, so this delay is what keeps the first CMD from
		 * racing the chip's power-on reset.
		 * 0x325aa0 = 3300000 uV.
		 */
		wl_on_reg: wl_on_reg {
			compatible = "regulator-fixed";
			regulator-name = "wl-on-regulator";
			regulator-min-microvolt = <0x325aa0>;
			regulator-max-microvolt = <0x325aa0>;
			gpio = <&gio 0x1c 0x00>;		/* line 28 = WL_ON */
			startup-delay-us = <0x249f0>;
			enable-active-high;
		};
		/* SODEV-LINUX-DOM0-SD-STRIP-END */

		/* Always-on fixed regulator for the Bluetooth controller's vbat/vddio.
		 * It has no GPIO and switches nothing; it exists because hci_bcm takes
		 * those supplies with devm_regulator_get() and a dom0less guest cannot
		 * fall back on dummy supplies (the guest DT root has no compatible, so
		 * has_full_constraints never becomes true and the core refuses them).
		 *
		 * It stays outside the strip blocks domd-vc4.bb deletes for DOM0_OS=linux.
		 * Its only users, the vbat-supply/vddio-supply references in the bluetooth
		 * node, are stripped for that flavour with the Bluetooth UART, so there it
		 * is merely unused. A definition stripped while a reference to it stayed
		 * would make dtc fail on phandle_references, and NO DTB would be produced
		 * for that flavour at all.
		 *
		 * DO NOT WRITE THE STRIP MARKER STRINGS IN A COMMENT. The recipe's sed
		 * deletes from the BEGIN pattern to the END pattern, and it matches
		 * comment text just as happily as the real markers: a comment naming the
		 * BEGIN marker starts a deletion that runs to the next END marker, and dtc
		 * then reports a syntax error for the linux flavour only.
		 *
		 * No xen,path / xen,reg / xen,force-assign-without-iommu: this is a purely
		 * virtual node with no MMIO, so it is not a passthrough target the way gio
		 * or the MMIO nodes are.
		 */
		bt_vbat_reg: bt-vbat-reg {
			compatible = "regulator-fixed";
			regulator-name = "bt-vbat";
			regulator-min-microvolt = <3300000>;
			regulator-max-microvolt = <3300000>;
			regulator-always-on;
			status = "okay";
		};

		/* SODEV-LINUX-DOM0-SD-STRIP-BEGIN: domd-vc4.bb strips this whole SD/GPIO
		 * block for DOM0_OS=linux. In the linux flavour the thin Linux
		 * Dom0 is the hardware domain and KEEPS the SoC SDHCI
		 * (mmc@fff000) + AON GPIO, mounting /dev/mmcblk0p1 and
		 * block-attaching p3/p4 to DomD (xvdb/xvdc). Only the zephyr
		 * flavour hands the SD to DomD, so only there does DomD need
		 * this block (which claims mmc IRQ SPI273 ->
		 * route_irq_to_guest). Comments are dropped by dtc, so the
		 * zephyr DTB is byte-identical with these markers. */
		/* ===== emmc2 clock (200 MHz), shared by TWO controllers =====
		 * It feeds mmc@1000fff000 (the SoC SD card controller, below)
		 * and mmc@1001100000 (the Wi-Fi SDIO controller, above).
		 * DOM0_OS=linux strips both, so it goes with them. 0xbebc200 =
		 * 200000000. Same value the host DTB gives emmc2.
		 */
		clk_emmc2: clk_emmc2 {
			compatible = "fixed-clock";
			#clock-cells = <0x0>;
			clock-output-names = "emmc2-clock";
			clock-frequency = <0xbebc200>;
		};

		/* ------------------------------------------------------------------
		 * SoC-internal SDHCI (SD card slot) passthrough
		 * to DomD. In the disaggregated topology the Dom0 is Zephyr (no blkback), so DomD owns the SD
		 * directly and its qemu serves /dev/mmcblk0p3 (DomU rootfs) /
		 * /dev/mmcblk0p4 (DomA super) as virtio-blk. Content ported verbatim
		 * from bcm2712-raspberrypi5-mmc.dtso (EPAM, same xen,reg/xen,path/
		 * force-assign conventions as the GPU nodes above). Includes the AON
		 * GPIO controller (gpio@7d517c00) that the SD card-detect and the two
		 * regulators depend on; boot.cmd no longer strips its xen,passthrough
		 * marker in the host DT (AON GPIO moves Dom0->DomD; the Zephyr Dom0
		 * does not use GPIO).
		 * ------------------------------------------------------------------ */
		mmc@1000fff000 {
			compatible = "brcm,bcm2712-sdhci";
			interrupt-parent = <&gic>;
			interrupts = <0x0 0x111 0x4>;
			reg-names = "host", "cfg", "busisol", "lcpll";
			reg = <0x10 0xfff000 0x0 0x260 0x10 0xfff400 0x0 0x200
			       0x10 0x15040b0 0x0 0x4 0x10 0x15200f0 0x0 0x24>;
			clocks = <&clk_emmc2>;
			clock-names = "sw_sdio";
			cd-gpios = <&gpio7d517c00 0x5 0x1>;
			sd-uhs-sdr104;
			sd-uhs-ddr50;
			sd-uhs-sdr50;
			bus-width = <0x4>;
			vmmc-supply = <&sd_vcc_reg>;
			vqmmc-supply = <&sd_io_1v8_reg>;
			mmc-ddr-3_3v;
			sdhci-caps = <0x0 0x0>;
			sdhci-caps-mask = <0xc000 0x0>;
			xen,path = "/soc@107c000000/mmc@fff000";
			xen,force-assign-without-iommu;
			/* busisol lives in host page 0x1504000, which is already mapped by
			 * reset-controller@1504318 above; drop the duplicate xen,reg entry so
			 * each host page is passed through exactly once (direct-map: the mmc
			 * driver still reaches busisol via that single mapping). */
			xen,reg = <0x10 0xfff000 0x0 0x1000 0x10 0xfff000
				   0x10 0x1520000 0x0 0x1000 0x10 0x1520000>;
			status = "okay";
		};

		sd_io_1v8_reg: sd_io_1v8_reg {
			compatible = "regulator-gpio";
			states = <0x1b7740 0x1 0x325aa0 0x0>;
			gpios = <&gpio7d517c00 0x3 0x0>;
			regulator-settling-time-us = <0x1388>;
			regulator-always-on;
			regulator-boot-on;
			regulator-max-microvolt = <0x325aa0>;
			regulator-min-microvolt = <0x1b7740>;
			regulator-name = "vdd-sd-io";
			status = "okay";
		};

		gpio7d517c00: gpio@107d517c00 {
			compatible = "brcm,brcmstb-gpio";
			#gpio-cells = <0x2>;
			gpio-controller;
			reg = <0x10 0x7d517c00 0x00 0x40>;
			brcm,gpio-direct;
			brcm,gpio-bank-widths = <0x11 0x6>;
			xen,path = "/soc@107c000000/gpio@7d517c00";
			xen,force-assign-without-iommu;
			xen,reg = <0x10 0x7d517000 0x0 0x1000 0x10 0x7d517000>;
		};

		sd_vcc_reg: sd_vcc_reg {
			compatible = "regulator-fixed";
			gpios = <&gpio7d517c00 0x4 0x0>;
			enable-active-high;
			regulator-boot-on;
			regulator-max-microvolt = <0x325aa0>;
			regulator-min-microvolt = <0x325aa0>;
			regulator-name = "vcc-sd";
			status = "okay";
		};
		/* SODEV-LINUX-DOM0-SD-STRIP-END */
	};
};
